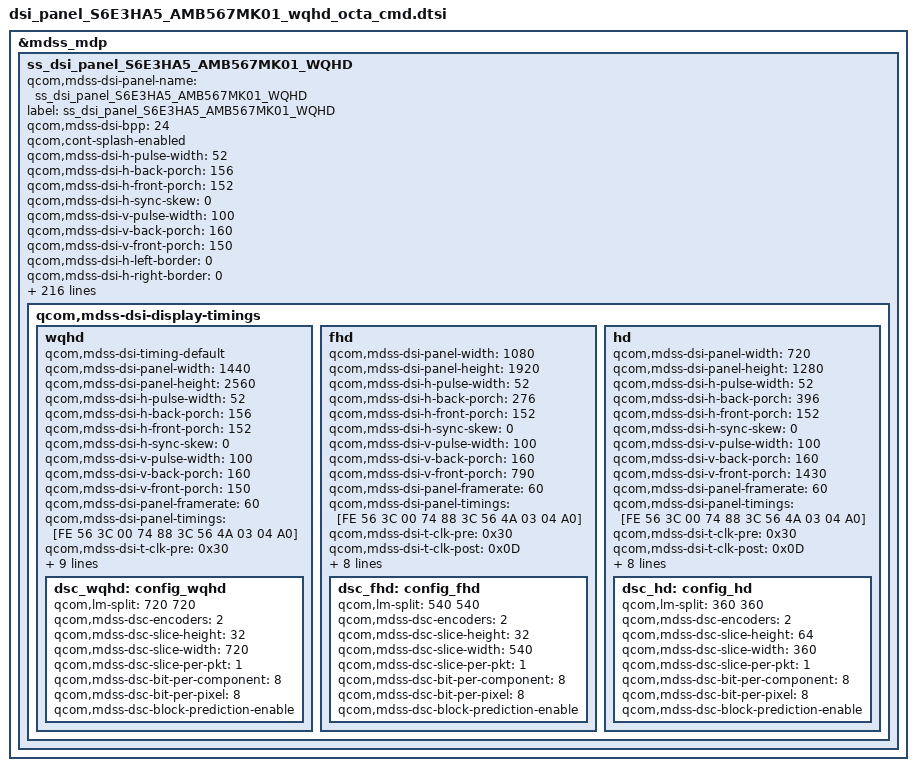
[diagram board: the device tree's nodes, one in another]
/* Copyright (c) 2012, Samsung Electronics Corporation. All rights reserved.
 *
 * This program is free software; you can redistribute it and/or modify
 * it under the terms of the GNU General Public License version 2 and
 * only version 2 as published by the Free Software Foundation.
 *
 * This program is distributed in the hope that it will be useful,
 * but WITHOUT ANY WARRANTY; without even the implied warranty of
 * MERCHANTABILITY or FITNESS FOR A PARTICULAR PURPOSE.  See the
 * GNU General Public License for more details.
 */

&mdss_mdp {
	ss_dsi_panel_S6E3HA5_AMB567MK01_WQHD: ss_dsi_panel_S6E3HA5_AMB567MK01_WQHD {
		qcom,mdss-dsi-panel-name = "ss_dsi_panel_S6E3HA5_AMB567MK01_WQHD";
		label = "ss_dsi_panel_S6E3HA5_AMB567MK01_WQHD";
		qcom,mdss-dsi-bpp = <24>;
		qcom,cont-splash-enabled;
		/*qcom,dcs-cmd-by-left;*/
		/*qcom,cmd-sync-wait-broadcast;*/
		/*qcom,cmd-sync-wait-trigger;*/
		/*qcom,mdss-dsi-fbc-enable=*/
		/*qcom,mdss-dsi-fbc-bpp=*/
		/*qcom,mdss-dsi-fbc-packing=*/
		/*qcom,mdss-dsi-fbc-quant-error=*/
		/*qcom,mdss-dsi-fbc-bias=*/
		/*qcom,mdss-dsi-fbc-pat-mode=*/
		/*qcom,mdss-dsi-fbc-vlc-mode=*/
		/*qcom,mdss-dsi-fbc-bflc-mode=*/
		/*qcom,mdss-dsi-fbc-h-line-budget=*/
		/*qcom,mdss-dsi-fbc-budget-ctrl=*/
		/*qcom,mdss-dsi-fbc-block-budget=*/
		/*qcom,mdss-dsi-fbc-lossless-threshold=*/
		/*qcom,mdss-dsi-fbc-lossy-threshold=*/
		/*qcom,mdss-dsi-fbc-rgb-threshold=*/
		/*qcom,mdss-dsi-fbc-lossy-mode-idx=*/

		qcom,mdss-dsi-h-pulse-width = <52>;
		qcom,mdss-dsi-h-back-porch = <156>;
		qcom,mdss-dsi-h-front-porch = <152>;
		qcom,mdss-dsi-h-sync-skew = <0>;
		qcom,mdss-dsi-v-pulse-width = <100>;
		qcom,mdss-dsi-v-back-porch = <160>;
		qcom,mdss-dsi-v-front-porch = <150>;

		qcom,mdss-dsi-h-left-border = <0>;
		qcom,mdss-dsi-h-right-border = <0>;
		qcom,mdss-dsi-v-top-border = <0>;
		qcom,mdss-dsi-v-bottom-border = <0>;

		qcom,mdss-dsi-underflow-color = <0xFF>;
		qcom,mdss-dsi-border-color = <0>;

		/*qcom,mdss-dsi-pan-enable-dynamic-fps=*/
		/*qcom,mdss-dsi-pan-fps-update=*/

		qcom,mdss-dsi-bl-pmic-control-type = "bl_ctrl_dcs";
		/*qcom,mdss-dsi-bl-pmic-bank-select=*/
		/*qcom,mdss-dsi-bl-pmic-pwm-frequency=*/
		/*qcom,mdss-dsi-pwm-gpio=*/

		qcom,mdss-dsi-bl-min-level = <1>;
		qcom,mdss-dsi-bl-max-level = <365>;
		qcom,mdss-brightness-max-level = <365>;
		qcom,mdss-dsi-interleave-mode = <0>;
		qcom,mdss-dsi-panel-type = "dsi_cmd_mode";

		/*qcom,mdss-dsi-te-check-enable; */
		qcom,mdss-dsi-te-using-te-pin;
		qcom,mdss-dsi-te-pin-select = <1>;

		/*qcom,dynamic-mode-switch-enabled;*/
		/*qcom,dynamic-mode-switch-type = "dynamic-switch-immediate";*/

		qcom,mdss-dsi-te-dcs-command = <1>;
		qcom,mdss-dsi-wr-mem-start = <0x2C>;
		qcom,mdss-dsi-wr-mem-continue = <0x3C>;

		/* CMD mode panel doesn't need below stuff */
		/*qcom,mdss-dsi-h-sync-pulse=*/
		/*qcom,mdss-dsi-hfp-power-mode=*/
		/*qcom,mdss-dsi-hbp-power-mode=*/
		/*qcom,mdss-dsi-hsa-power-mode=*/
		/*qcom,mdss-dsi-last-line-interleave=*/
		/*qcom,mdss-dsi-bllp-eof-power-mode=*/
		/*qcom,mdss-dsi-bllp-power-mode=*/
		/*qcom,mdss-dsi-traffic-mode=*/

		qcom,mdss-dsi-pixel-packing = "loose";

		qcom,mdss-dsi-virtual-channel-id = <0>;
		qcom,mdss-dsi-color-order = "rgb_swap_rgb";
		qcom,mdss-dsi-lane-0-state;
		qcom,mdss-dsi-lane-1-state;
		qcom,mdss-dsi-lane-2-state;
		qcom,mdss-dsi-lane-3-state;
		qcom,mdss-dsi-lane-map = "lane_map_0123";

		/* 60 FPS - DSC (width 480) */
		qcom,mdss-dsi-t-clk-pre = <0x30>;
		qcom,mdss-dsi-t-clk-post = <0xD>;

		qcom,mdss-dsi-stream = <0>;
		qcom,mdss-dsi-mdp-trigger = "none";
		qcom,mdss-dsi-dma-trigger = "trigger_sw";
		qcom,mdss-dsi-panel-framerate = <60>;
/*		qcom,mdss-dsi-panel-clockrate = <898000000>;*/
		qcom,mdss-dsi-off-command-state = "dsi_hs_mode";

		qcom,mdss-pan-physical-width-dimension = <71>; /* 70.73 */
		qcom,mdss-pan-physical-height-dimension = <125>; /* 125.44 */

		qcom,mdss-dsi-panel-mode-gpio-state = "invalid";

		/*qcom,mdss-tear-check-disable*/
/*		qcom,mdss-tear-check-sync-cfg-height = <2576>; */
		/*qcom,mdss-tear-check-sync-init-val=*/
		/*qcom,mdss-tear-check-sync-threshold-start=*/
		/*qcom,mdss-tear-check-sync-threshold-continue=*/
		/*qcom,mdss-tear-check-start-pos=*/
		/*qcom,mdss-tear-check-rd-ptr-trigger-intr=*/
		/*qcom,mdss-tear-check-frame-rate=*/

		qcom,mdss-dsi-reset-sequence = <1 5>, <0 5>, <1 5>;
		qcom,partial-update-enabled;
		/*qcom,partial-update-roi-merge;*/
		/*qcom,mdss-dsi-horizontal-line-idle*/

		qcom,mdss-dsi-lp11-init;
		qcom,mdss-dsi-init-delay-us = <1000>;

		qcom,mdss-dsi-rx-eot-ignore;
		qcom,mdss-dsi-tx-eot-append;

		qcom,ulps-enabled;
		/* qcom,suspend-ulps-enabled; */
		qcom,esd-check-enabled;
		qcom,mdss-dsi-panel-status-check-mode ="reg_read_irq";
		qcom,mdss-dsi-panel-status-value=<1>;
		/*qcom,mdss-dsi-panel-status-irq-trigger1 = "rising";*/
		qcom,mdss-dsi-panel-status-irq-trigger1 = "falling";

		qcom,mdss-dsi-off-command=[
			05 01 00 00 00 00 02 28 00
			29 01 00 00 00 00 03 9F A5 A5		/* LV1 (9F) unlock */
			05 01 00 00 00 00 02 10 00			/* wait 120ms(0x78) */
			29 01 00 00 78 00 03 9F 5A 5A		/* LV1 (9F) lock */
		];

		samsung,esd_recovery_1_tx_cmds_revA = [
			0A 01 00 00 00 00 58				/* PPS setting */
				11 00 00 89 30 80 0A
				00 05 A0 00 40 01 68
				01 68 02 00 01 B4 00
				20 04 F2 00 05 00 0C
				01 87 02 63 18 00 10
				F0 03 0C 20 00 06 0B
				0B 33 0E 1C 2A 38 46
				54 62 69 70 77 79 7B
				7D 7E 01 02 01 00 09
				40 09 BE 19 FC 19 FA
				19 F8 1A 38 1A 78 1A
				B6 2A F6 2B 34 2B 74
				3B 74 6B F4
		];

		samsung,esd_recovery_2_tx_cmds_revA = [
			0A 01 00 00 00 00 58				/* PPS setting */
				11 00 00 89 30 80 0A
				00 05 A0 00 40 01 68
				01 68 02 00 01 B4 00
				20 04 F2 00 05 00 0C
				01 87 02 63 18 00 10
				F0 03 0C 20 00 06 0B
				0B 33 0E 1C 2A 38 46
				54 62 69 70 77 79 7B
				7D 7E 01 02 01 00 09
				40 09 BE 19 FC 19 FA
				19 F8 1A 38 1A 78 1A
				B6 2A F6 2B 34 2B 74
				3B 74 6B F4
		];

		/*qcom,dynamic-mode-switch-enabled*/
		/*qcom,video-to-cmd-mode-switch-commands=*/
		/*qcom,cmd-to-video-mode-switch-commands=*/

/*
* ************************************************************************************************************************************
*
*
*			Below  parameters are samsung dependent thigs
*
*
* ************************************************************************************************************************************
*/
		samsung,support_panel_max = <1>;
		samsung,hw-config = "single_dsi";
		samsung,panel-lpm-enable;
		samsung,support_irc;
		samsung,elvss_interpolation_temperature = <(-15)>;
		samsung,support_factory_panel_swap;
		samsung,support_multires;

		/*
		* ************************************************************************************************************************
		*  Tx
		* ************************************************************************************************************************
		*/

		samsung,level1_key_enable_tx_cmds_revA = [
			29 01 00 00 00 00 03 F0 5A 5A
		];
		samsung,level1_key_disable_tx_cmds_revA = [
			29 01 00 00 00 00 03 F0 A5 A5
		];
		samsung,level2_key_enable_tx_cmds_revA = [
			29 01 00 00 00 00 03 F2 5A 5A
		];
		samsung,level2_key_disable_tx_cmds_revA = [
			29 01 00 00 00 00 03 F2 A5 A5
		];

		samsung,packet_size_tx_cmds_revA = [
			37 01 00 00 00 00 02 07 00
		];

		samsung,reg_read_pos_tx_cmds_revA = [
			15 01 00 00 00 00 02 B0 00
		];

		samsung,manufacture_read_pre_tx_cmds_revA = [
			05 01 00 00 78 00 01 11
			29 01 00 00 00 00 03 F0 5A 5A
		];

		samsung,display_on_tx_cmds_revA = [
			29 01 00 00 00 00 03 9F A5 A5		/* LV1 (9F) unlock */
			05 01 00 00 00 00 02 29 00
			29 01 00 00 00 00 03 9F 5A 5A		/* LV1 (9F) lock */
		];
		samsung,display_off_tx_cmds_revA = [05 01 00 00 00 00 02 28 00];

		/*
		* ************************************************************************************************************************
		*  Rx
		* ************************************************************************************************************************
		*/

		/*
			the last byte in read commands	represent READ LENGH, like below  READ LENGH = 0x21
		*/

		samsung,manufacture_id0_rx_cmds_revA = [ 06 01 00 00 00 00 01 da 01 00];
		samsung,manufacture_id1_rx_cmds_revA = [ 06 01 00 00 00 00 01 db 01 00];
		samsung,manufacture_id2_rx_cmds_revA = [ 06 01 00 00 00 00 01 dc 01 00];

		samsung,manufacture_id_rx_cmds_revA = [ 06 01 00 00 00 00 01 04 03 00];

		samsung,manufacture_date_rx_cmds_revA = [ 06 01 00 00 00 00 01 c8 04 28];	/* read C8 41~44th , 40=0x28*/

		samsung,cell_id_rx_cmds_revA = [ 06 01 00 00 00 00 01 C8 07 28]; /* read C8 41th~47th */
		samsung,octa_id_rx_cmds_revA = [ 06 01 00 00 00 00 01 C9 14 01]; /* read C9 2th~21th */

		samsung,ddi_id_rx_cmds_revA = [ 06 01 00 00 00 00 01 D6 05 00]; /* read D6 1th~5th */

		samsung,ldi_debug0_rx_cmds_revA = [06 01 00 00 00 00 01 0A 01 00];
		samsung,ldi_debug1_rx_cmds_revA = [06 01 00 00 00 00 01 ED 01 00];
		samsung,ldi_debug2_rx_cmds_revA = [06 01 00 00 00 00 01 EE 01 00];

		samsung,mtp_read_sysfs_rx_cmds_revA = [ 06 01 00 00 00 00 01 00 00 00];

		samsung,smart_dimming_mtp_rx_cmds_revA = [ 06 01 00 00 00 00 01 c8 23 00];

		samsung,mdnie_read_rx_cmds_revA = [ 06 01 00 00 00 00 01 A1 04 00];

		samsung,spi_enable_tx_cmds_revA = [
			29 01 00 00 00 00 03 F0 5A 5A
			29 01 00 00 00 00 03 FC 5A 5A
			29 01 00 00 00 00 02 B0 13
			29 01 00 00 00 00 02 D8 02
			29 01 00 00 00 00 02 B0 1F
			29 01 00 00 1E 00 02 FE 06
			29 01 00 00 00 00 03 F0 A5 A5
			29 01 00 00 00 00 03 FC A5 A5
		];

		/*
		* ************************************************************************************************************************
		*  SAMSUNG PANEL COVER CONTROL
		* ************************************************************************************************************************
		*/

		samsung,panel_cover_control_enable_cmds_revA = [
			29 01 00 00 00 00 03 F0 5A 5A
			29 01 00 00 00 00 02 B0 04
			29 01 00 00 00 00 03 F2 29 F0		/* LDI FPS Change(40.47hz) */
			29 01 00 00 00 00 03 F0 A5 A5
		];

		samsung,panel_cover_control_disable_cmds_revA = [
			29 01 00 00 00 00 03 F0 5A 5A
			29 01 00 00 00 00 02 B0 04
			29 01 00 00 00 00 03 F2 1C 70		/* LDI FPS Recovery(59.835hz) */
			29 01 00 00 00 00 03 F0 A5 A5
		];

		/*
		 * ************************************************************************************************************************
		 *   APLPM
		 * ************************************************************************************************************************
		 */

		/*
		 * The command set of R53h will be replaced with
		 * lpm 2nit or 40nit tx commnad for
		 * changing brightness level
		 */
		samsung,alpm_on_tx_cmds_revA = [
			29 01 00 00 00 00 03 F0 5A 5A		/* TEST KEY Enable */

			/* mDNIe BYPASS */
			39 01 00 00 00 00 38
				DF 00 6A 9A 25 1A 16 2A 00 37
				5A 00 4E C5 00 5D 17 00 30 C3
				FF 00 00 FF FF 00 FF 00 FF FF
				FF FF 00 FF FF 00 FF 00 FF 00
				00 FF FF 00 FF 00 FF 00 00 FF
				FF 00 FF 00 FF 00
			39 01 00 00 00 00 B8
				DE 00 00 00 24 96 B3 01 0E 01
				00 77 03 07 40 08 04 04 00 00
				0D E1 07 29 04 0F A0 00 03 7A
				A0 00 25 1C 24 00 48 EA FA 00
				10 00 10 00 9C 01 00 00 00 00
				DC 03 FF 40 80 C0 00 9A 00 9A
				00 9A 00 9A 00 00 00 00 00 00
				00 00 40 80 C0 01 0E 01 0E 01
				0E 01 0E 00 00 00 00 00 00 00
				00 01 0E 01 3A 01 44 00 01 00
				43 00 4B 00 18 00 1C 01 FF 01
				FF 03 FF E8 03 FF E8 80 00 28
				A0 01 00 01 00 01 00 00 10 00
				00 30 00 00 00 30 00 00 30 00
				00 00 FF 00 00 02 00 02 00 14
				00 01 00 01 00 10 00 00 28 3C
				01 00 00 10 20 30 40 50 60 70
				80 90 A0 B0 C0 D0 E0 F0 01 00
				00 00 00 00
			39 01 00 00 00 00 0F
				DD 01 00 08 00 00 00 00 00 00
				00 00 00 00 00

			29 01 00 00 00 00 02 B0 07			/* Global para(8th) */
			29 01 00 00 00 00 02 BB C1			/* ALPM(0xC1) Mode On */

			/* For TEST */
			29 01 00 00 00 00 02 B0 09			/* Global para(10th) */
			29 01 00 00 00 00 02 BB 0C			/* EQ Control */
			29 01 00 00 00 00 02 B0 0E			/* Global para(15th) */
			29 01 00 00 00 00 05 BB 07 07 07 07	/* EQ Control */
			29 01 00 00 00 00 02 B0 01			/* Global para(2nd) */
			29 01 00 00 00 00 02 F6 03			/* SAP Setting */

			29 01 00 00 00 00 02 53 03			/* ALPM/HLPM 2nit On*/
			29 01 00 00 00 00 03 B8 00 00		/* IRC OFF */
			29 01 00 00 01 00 02 F7 03			/* Gamma, LTPS(AID) update */
			29 01 00 00 00 00 02 F7 00
			29 01 00 00 00 00 03 F0 A5 A5
		];

		samsung,alpm_off_tx_cmds_revA = [
			29 01 00 00 00 00 03 F0 5A 5A	/* TEST KEY Enable */
			05 01 00 00 00 00 02 28 00		/* display off */
			/* image write for normal mode */
			29 01 00 00 23 00 02 53 00		/* HLPM/ALPM off & Wait 35ms(0x23ms) */
			29 01 00 00 01 00 02 F7 03		/* Gamma, LTPS(AID) update */
			29 01 00 00 00 00 02 F7 00
			29 01 00 00 00 00 03 F0 A5 A5	/* TEST KEY Disable */
		];

		samsung,lpm_2nit_tx_cmds_revA = [29 01 00 00 00 00 02 53 03];
		samsung,lpm_60nit_tx_cmds_revA = [29 01 00 00 00 00 02 53 02];

		samsung,lpm_ctrl_alpm_2nit_tx_cmds_revA = [29 01 00 00 00 00 02 BB C1];
		samsung,lpm_ctrl_alpm_60nit_tx_cmds_revA = [29 01 00 00 00 00 02 BB 81];
		samsung,lpm_ctrl_hlpm_2nit_tx_cmds_revA = [29 01 00 00 00 00 02 BB 41];
		samsung,lpm_ctrl_hlpm_60nit_tx_cmds_revA = [29 01 00 00 00 00 02 BB 01];

		/*
		* ************************************************************************************************************************
		*  VINT
		* ************************************************************************************************************************
		*/

		samsung,vint_tx_cmds_revA = [
			29 01 00 00 00 00 03 F4 BB 1E /* 420 ~ 14cd 0 */
			29 01 00 00 00 00 03 F4 BB 1D /* 13cd 1 */
			29 01 00 00 00 00 03 F4 BB 1C /* 12cd 2 */
			29 01 00 00 00 00 03 F4 BB 1B /* 11cd 3 */
			29 01 00 00 00 00 03 F4 BB 1A /* 10cd 4 */
			29 01 00 00 00 00 03 F4 BB 19 /* 9cd 5 */
			29 01 00 00 00 00 03 F4 BB 18 /* 8cd 6 */
			29 01 00 00 00 00 03 F4 BB 17 /* 7cd 7 */
			29 01 00 00 00 00 03 F4 BB 16 /* 6cd 8 */
			29 01 00 00 00 00 03 F4 BB 15 /* 5 ~ 2cd 9 */
		];

		samsung,vint_map_table_revA = <
			2	9		3	9		4	9		5	9		6	8
			7	7		8	6		9	5		10	4		11	3
			12	2		13	1		14	0		15	0		16	0
			17	0		19	0		20	0		21	0		22	0
			24	0		25	0		27	0		29	0		30	0
			32	0		34	0		37	0		39	0		41	0
			44	0		47	0		50	0		53	0		56	0
			60	0		64	0		68	0		72	0		77	0
			82	0		87	0		93	0		98	0		105	0
			111	0		119	0		126	0		134	0		143	0
			152	0		162	0		172	0		183	0		195	0
			207	0		220	0		234	0		249	0		265	0
			282	0		300	0		316	0		333	0		350	0
			357	0		365	0		372	0		380	0		387	0
			395	0		403	0		412	0		420	0
		>;

		/*
		* ************************************************************************************************************************
		*  GAMMA
		* ************************************************************************************************************************
		*/

		samsung,gamma_tx_cmds_revA = [
			29 01 00 00 00 00 24		/* Brightness Condition Set - Gamma 2.2 Setting*/
			CA 01 00 01 00 01 00 80
			80 80 80 80 80 80 80 80
			80 80 80 80 80 80 80 80
			80 80 80 80 80 80 80 00
			00 00 00 00
			29 01 00 00 00 00 02 F7 03		/* Gamma, LTPS(AID) update */

			29 01 00 00 00 00 3C		/* dummy for single transmission more 100ns delay */
			00 00 00 00 00 00 00 00 00 00
			00 00 00 00 00 00 00 00 00 00
			00 00 00 00 00 00 00 00 00 00
			00 00 00 00 00 00 00 00 00 00
			00 00 00 00 00 00 00 00 00 00
			00 00 00 00 00 00 00 00 00 00

			29 01 00 00 00 00 02 F7 00
		];

		/*
		* ************************************************************************************************************************
		*  HBM
		* ************************************************************************************************************************
		*/

		samsung,enter_hbm_lux = <10000>;
		samsung,hbm_rx_cmds_revA = [ 06 01 00 00 00 00 01 B3 21 02];	/* read B3 3rd~35th , 2=0x02 */
		samsung,hbm2_rx_cmds_revA = [ 06 01 00 00 00 00 01 B3 21 02];	/* read B3 3rd~35th , 2=0x02 */

		samsung,hbm_gamma_tx_cmds_revA = [
			29 01 00 00 00 00 24		/* Brightness Condition Set - Gamma 2.2 Setting*/
				CA 01 00 01 00 01 00 80
				80 80 80 80 80 80 80 80
				80 80 80 80 80 80 80 80
				80 80 80 80 80 80 80 00
				00 00 00 00
		];

		samsung,hbm_etc_tx_cmds_revA = [
			29 01 00 00 00 00 03 B1 00 0C		/* AID */
			29 01 00 00 00 00 04 B5 19 BC 00	/* ELVSS Setting */
			29 01 00 00 00 00 02 B0 17			/* Global para(24th) */
			29 01 00 00 00 00 02 B5 00 			/* ELVSS offset */
			29 01 00 00 00 00 03 F4 BB 1E		/* VINT set */
			29 01 00 00 00 00 08 B4 00 55 99 00 00 27 0A			/* ACL OPR Average Setting */
			29 01 00 00 00 00 02 55 02			/* ACL On */
			29 01 00 00 00 00 02 F7 03
			29 01 00 00 00 00 02 F7 00
		];

		samsung,hbm_irc_tx_cmds_revA = [
			29 00 00 00 00 00 15 B8 00 00
				00 00 00 00 00 00 00 00 00
				00 00 00 00 00 00 00 00 00
		];

		samsung,panel-hbm-off-cmds_revA = [
			15 01 00 00 00 00 02 53 00		/* HBM off*/
		];

		samsung,ccb_on_tx_cmds_revA = [
			29 01 00 00 00 00 03 F0 5A 5A
			29 00 00 00 00 00 03 B7 00 2A
			29 01 00 00 00 00 03 F0 A5 A5
		];

		samsung,ccb_off_tx_cmds_revA = [
			29 01 00 00 00 00 03 F0 5A 5A
			29 00 00 00 00 00 03 B7 00 2A
			29 01 00 00 00 00 03 F0 A5 A5
		];

		/*
		* ************************************************************************************************************************
		*  IRC
		* ************************************************************************************************************************
		*/

		samsung,irc_off_tx_cmds_revA = [
			29 01 00 00 00 00 02 B8 00	 /* IRC OFF */
		];

		samsung,irc_subdivision_tx_cmds_revA = [
			29 01 00 00 00 00 15 B8 6D B0 48 4C 95 DA 33 69 12 7A DA 00 00 00 00 00 00 00 00 00  /* 00 */
			29 01 00 00 00 00 15 B8 6D B0 48 4C 95 DA 33 69 12 7A DA 00 00 00 00 00 00 00 00 00  /* 01 */
			29 01 00 00 00 00 15 B8 6D B0 48 4C 95 DA 33 69 12 7A DA 00 00 00 00 00 00 00 00 00  /* 02 */
			29 01 00 00 00 00 15 B8 6D B0 48 4C 95 DA 33 69 12 7A DA 00 00 00 00 00 00 00 00 00  /* 03 */
			29 01 00 00 00 00 15 B8 6D B0 48 4C 95 DA 33 69 12 7A DA 00 00 00 00 00 00 00 00 00  /* 04 */
			29 01 00 00 00 00 15 B8 6D B0 48 4C 95 DA 33 69 12 7A DA 00 00 00 00 00 00 00 00 00  /* 05 */
			29 01 00 00 00 00 15 B8 6D B0 48 4C 95 DA 33 69 12 7A DA 00 00 00 00 00 00 00 00 00  /* 06 */
			29 01 00 00 00 00 15 B8 6D B0 48 4C 95 DA 33 69 12 7A DA 00 00 00 00 00 00 00 00 00  /* 07 */
			29 01 00 00 00 00 15 B8 6D B0 48 4C 95 DA 33 69 12 7A DA 00 00 00 00 00 00 00 00 00  /* 08 */
			29 01 00 00 00 00 15 B8 6D B0 48 4C 95 DA 33 69 12 7A DA 00 00 00 00 00 00 00 00 00  /* 09 */
			29 01 00 00 00 00 15 B8 6D B0 48 4C 95 DA 33 69 12 7A DA 00 00 00 00 00 00 00 00 00  /* 10 */
			29 01 00 00 00 00 15 B8 6D B0 48 4C 95 DA 33 69 12 7A DA 00 00 00 00 00 00 00 00 00  /* 11 */
			29 01 00 00 00 00 15 B8 6D B0 48 4C 95 DA 33 69 12 7A DA 00 00 00 00 00 00 00 00 00  /* 12 */
			29 01 00 00 00 00 15 B8 6D B0 48 4C 95 DA 33 69 12 7A DA 00 00 00 00 00 00 00 00 00  /* 13 */
			29 01 00 00 00 00 15 B8 6D B0 48 4C 95 DA 33 69 12 7A DA 00 00 00 00 00 00 00 00 00  /* 14 */
			29 01 00 00 00 00 15 B8 6D B0 48 4C 95 DA 33 69 12 7A DA 00 00 00 00 00 00 00 00 00  /* 15 */
			29 01 00 00 00 00 15 B8 6D B0 48 4C 95 DA 33 69 12 7A DA 00 00 00 00 00 00 00 00 00  /* 16 */
			29 01 00 00 00 00 15 B8 6D B0 48 4C 95 DA 33 69 12 7A DA 00 00 00 00 00 00 00 00 00  /* 17 */
			29 01 00 00 00 00 15 B8 6D B0 48 4C 95 DA 33 69 12 7A DA 00 00 00 00 00 00 00 00 00  /* 18 */
			29 01 00 00 00 00 15 B8 6D B0 48 4C 95 DA 33 69 12 7A DA 00 00 00 00 00 00 00 00 00  /* 19 */
			29 01 00 00 00 00 15 B8 6D B0 48 4C 95 DA 33 69 12 7A DA 00 00 00 00 00 00 00 00 00  /* 20 */
			29 01 00 00 00 00 15 B8 6D B0 48 4C 95 DA 33 69 12 7A DA 00 00 00 00 00 00 00 00 00  /* 21 */
			29 01 00 00 00 00 15 B8 6D B0 48 4C 95 DA 33 69 12 7A DA 00 00 00 00 00 00 00 00 00  /* 22 */
			29 01 00 00 00 00 15 B8 6D B0 48 4C 95 DA 33 69 12 7A DA 00 00 00 00 00 00 00 00 00  /* 23 */
			29 01 00 00 00 00 15 B8 6D B0 48 4C 95 DA 33 69 12 7A DA 00 00 00 00 00 00 00 00 00  /* 24 */
			29 01 00 00 00 00 15 B8 6D B0 48 4C 95 DA 33 69 12 7A DA 00 00 00 00 00 00 00 00 00  /* 25 */
			29 01 00 00 00 00 15 B8 6D B0 48 4C 95 DA 33 69 12 7A DA 00 00 00 00 00 00 00 00 00  /* 26 */
			29 01 00 00 00 00 15 B8 6D B0 48 4C 95 DA 33 69 12 7A DA 00 00 00 00 00 00 00 00 00  /* 27 */
			29 01 00 00 00 00 15 B8 6D B0 48 4C 95 DA 33 69 12 7A DA 00 00 00 00 00 00 00 00 00  /* 28 */
			29 01 00 00 00 00 15 B8 6D B0 48 4C 95 DA 33 69 12 7A DA 00 00 00 00 00 00 00 00 00  /* 29 */
			29 01 00 00 00 00 15 B8 6D B0 48 4C 95 DA 33 69 12 7A DA 00 00 00 00 00 00 00 00 00  /* 30 */
			29 01 00 00 00 00 15 B8 6D B0 48 4C 95 DA 33 69 12 7A DA 00 00 00 00 00 00 00 00 00  /* 31 */
			29 01 00 00 00 00 15 B8 6D B0 48 4C 95 DA 33 69 12 7A DA 00 00 00 00 00 00 00 00 00  /* 32 */
			29 01 00 00 00 00 15 B8 6D B0 48 4C 95 DA 33 69 12 7A DA 00 00 00 00 00 00 00 00 00  /* 33 */
			29 01 00 00 00 00 15 B8 6D B0 48 4C 95 DA 33 69 12 7A DA 00 00 00 00 00 00 00 00 00  /* 34 */
			29 01 00 00 00 00 15 B8 6D B0 48 4C 95 DA 33 69 12 7A DA 00 00 00 00 00 00 00 00 00  /* 35 */
			29 01 00 00 00 00 15 B8 6D B0 48 4C 95 DA 33 69 12 7A DA 00 00 00 00 00 00 00 00 00  /* 36 */
			29 01 00 00 00 00 15 B8 6D B0 48 4C 95 DA 33 69 12 7A DA 00 00 00 00 00 00 00 00 00  /* 37 */
			29 01 00 00 00 00 15 B8 6D B0 48 4C 95 DA 33 69 12 7A DA 00 00 00 00 00 00 00 00 00  /* 38 */
			29 01 00 00 00 00 15 B8 6D B0 48 4C 95 DA 33 69 12 7A DA 02 02 02 01 01 00 00 01 01  /* 39 */
			29 01 00 00 00 00 15 B8 6D B0 48 4C 95 DA 33 69 12 7A DA 02 02 02 01 01 00 00 01 01  /* 40 */
			29 01 00 00 00 00 15 B8 6D B0 48 4C 95 DA 33 69 12 7A DA 02 02 02 01 01 01 01 01 00  /* 41 */
			29 01 00 00 00 00 15 B8 6D B0 48 4C 95 DA 33 69 12 7A DA 02 02 02 01 01 01 01 01 00  /* 42 */
			29 01 00 00 00 00 15 B8 6D B0 48 4C 95 DA 33 69 12 7A DA 02 02 02 01 01 01 01 01 00  /* 43 */
			29 01 00 00 00 00 15 B8 6D B0 48 4C 95 DA 33 69 12 7A DA 02 02 02 01 01 01 01 01 00  /* 44 */
			29 01 00 00 00 00 15 B8 6D B0 48 4C 95 DA 33 69 12 7A DA 03 03 02 01 01 01 00 01 01  /* 45 */
			29 01 00 00 00 00 15 B8 6D B0 48 4C 95 DA 33 69 12 7A DA 03 03 02 01 01 01 00 01 01  /* 46 */
			29 01 00 00 00 00 15 B8 6D B0 48 4C 95 DA 33 69 12 7A DA 03 03 03 01 01 00 01 01 01  /* 47 */
			29 01 00 00 00 00 15 B8 6D B0 48 4C 95 DA 33 69 12 7A DA 03 03 03 01 01 00 01 01 01  /* 48 */
			29 01 00 00 00 00 15 B8 6D B0 48 4C 95 DA 33 69 12 7A DA 03 03 03 01 01 01 01 01 00  /* 49 */
			29 01 00 00 00 00 15 B8 6D B0 48 4C 95 DA 33 69 12 7A DA 03 03 03 01 01 01 01 01 00  /* 50 */
			29 01 00 00 00 00 15 B8 6D B0 48 4C 95 DA 33 69 12 7A DA 03 03 03 01 02 01 01 01 00  /* 51 */
			29 01 00 00 00 00 15 B8 6D B0 48 4C 95 DA 33 69 12 7A DA 03 03 03 01 02 01 01 01 00  /* 52 */
			29 01 00 00 00 00 15 B8 6D B0 48 4C 95 DA 33 69 12 7A DA 04 03 03 01 02 01 01 01 01  /* 53 */
			29 01 00 00 00 00 15 B8 6D B0 48 4C 95 DA 33 69 12 7A DA 04 03 03 01 02 01 01 01 01  /* 54 */
			29 01 00 00 00 00 15 B8 6D B0 48 4C 95 DA 33 69 12 7A DA 04 04 03 01 01 01 01 01 01  /* 55 */
			29 01 00 00 00 00 15 B8 6D B0 48 4C 95 DA 33 69 12 7A DA 04 04 03 01 01 02 01 02 00  /* 56 */
			29 01 00 00 00 00 15 B8 6D B0 48 4C 95 DA 33 69 12 7A DA 04 04 04 01 02 01 01 01 01  /* 57 */
			29 01 00 00 00 00 15 B8 6D B0 48 4C 95 DA 33 69 12 7A DA 04 04 04 02 02 01 01 01 01  /* 58 */
			29 01 00 00 00 00 15 B8 6D B0 48 4C 95 DA 33 69 12 7A DA 04 04 04 02 02 01 01 01 01  /* 59 */
			29 01 00 00 00 00 15 B8 6D B0 48 4C 95 DA 33 69 12 7A DA 05 04 04 01 02 01 01 02 01  /* 60 */
			29 01 00 00 00 00 15 B8 6D B0 48 4C 95 DA 33 69 12 7A DA 05 04 04 01 02 01 01 02 01  /* 61 */
			29 01 00 00 00 00 15 B8 6D B0 48 4C 95 DA 33 69 12 7A DA 05 05 04 01 02 02 01 01 00  /* 62 */
			29 01 00 00 00 00 15 B8 6D B0 48 4C 95 DA 33 69 12 7A DA 05 05 04 02 02 02 01 01 01  /* 63 */
			29 01 00 00 00 00 15 B8 6D B0 48 4C 95 DA 33 69 12 7A DA 05 05 05 02 02 01 01 02 01  /* 64 */
			29 01 00 00 00 00 15 B8 6D B0 48 4C 95 DA 33 69 12 7A DA 05 05 05 02 02 01 01 02 01  /* 65 */
			29 01 00 00 00 00 15 B8 6D B0 48 4C 95 DA 33 69 12 7A DA 05 05 05 02 02 01 01 02 01  /* 66 */
			29 01 00 00 00 00 15 B8 6D B0 48 4C 95 DA 33 69 12 7A DA 06 05 05 01 03 02 02 01 01  /* 67 */
			29 01 00 00 00 00 15 B8 6D B0 48 4C 95 DA 33 69 12 7A DA 06 06 05 02 02 02 01 02 01  /* 68 */
			29 01 00 00 00 00 15 B8 6D B0 48 4C 95 DA 33 69 12 7A DA 06 06 05 02 02 02 01 02 01  /* 69 */
			29 01 00 00 00 00 15 B8 6D B0 48 4C 95 DA 33 69 12 7A DA 06 06 06 02 03 01 02 02 01  /* 70 */
			29 01 00 00 00 00 15 B8 6D B0 48 4C 95 DA 33 69 12 7A DA 06 06 06 02 03 02 02 02 01  /* 71 */
			29 01 00 00 00 00 15 B8 6D B0 48 4C 95 DA 33 69 12 7A DA 07 06 06 02 03 02 01 02 01  /* 72 */
			29 01 00 00 00 00 15 B8 6D B0 48 4C 95 DA 33 69 12 7A DA 07 07 06 02 03 02 02 02 01  /* 73 */
			29 01 00 00 00 00 15 B8 6D B0 48 4C 95 DA 33 69 12 7A DA 07 07 06 02 03 02 02 02 01  /* 74 */
			29 01 00 00 00 00 15 B8 6D B0 48 4C 95 DA 33 69 12 7A DA 07 07 07 03 03 02 02 03 01  /* 75 */
			29 01 00 00 00 00 15 B8 6D B0 48 4C 95 DA 33 69 12 7A DA 08 07 07 02 04 02 02 02 01  /* 76 */
			29 01 00 00 00 00 15 B8 6D B0 48 4C 95 DA 33 69 12 7A DA 08 08 07 02 03 02 02 02 02  /* 77 */
			29 01 00 00 00 00 15 B8 6D B0 48 4C 95 DA 33 69 12 7A DA 08 08 07 03 03 02 02 03 02  /* 78 */
			29 01 00 00 00 00 15 B8 6D B0 48 4C 95 DA 33 69 12 7A DA 08 08 07 03 04 03 02 02 01  /* 79 */
			29 01 00 00 00 00 15 B8 6D B0 48 4C 95 DA 33 69 12 7A DA 08 08 08 03 04 02 02 02 01  /* 80 */
			29 01 00 00 00 00 15 B8 6D B0 48 4C 95 DA 33 69 12 7A DA 09 09 08 03 03 02 02 03 02  /* 81 */
			29 01 00 00 00 00 15 B8 6D B0 48 4C 95 DA 33 69 12 7A DA 09 09 08 03 04 03 02 02 01  /* 82 */
			29 01 00 00 00 00 15 B8 6D B0 48 4C 95 DA 33 69 12 7A DA 0A 09 08 02 04 03 03 03 02  /* 83 */
			29 01 00 00 00 00 15 B8 6D B0 48 4C 95 DA 33 69 12 7A DA 0A 0A 09 03 04 02 02 02 02  /* 84 */
			29 01 00 00 00 00 15 B8 6D B0 48 4C 95 DA 33 69 12 7A DA 0A 0A 09 03 04 03 03 03 02  /* 85 */
			29 01 00 00 00 00 15 B8 6D B0 48 4C 95 DA 33 69 12 7A DA 0A 0A 09 04 04 03 02 04 02  /* 86 */
			29 01 00 00 00 00 15 B8 6D B0 48 4C 95 DA 33 69 12 7A DA 0B 0B 0A 03 04 03 03 03 01  /* 87 */
			29 01 00 00 00 00 15 B8 6D B0 48 4C 95 DA 33 69 12 7A DA 0B 0B 0A 03 04 03 03 04 02  /* 88 */
			29 01 00 00 00 00 15 B8 6D B0 48 4C 95 DA 33 69 12 7A DA 0B 0B 0A 04 05 03 03 03 02  /* 89 */
			29 01 00 00 00 00 15 B8 6D B0 48 4C 95 DA 33 69 12 7A DA 0C 0B 0A 03 05 04 03 04 02  /* 90 */
			29 01 00 00 00 00 15 B8 6D B0 48 4C 95 DA 33 69 12 7A DA 0C 0C 0B 04 05 03 03 03 02  /* 91 */
			29 01 00 00 00 00 15 B8 6D B0 48 4C 95 DA 33 69 12 7A DA 0C 0C 0B 04 05 04 03 04 02  /* 92 */
			29 01 00 00 00 00 15 B8 6D B0 48 4C 95 DA 33 69 12 7A DA 0D 0D 0B 04 05 04 03 04 02  /* 93 */
			29 01 00 00 00 00 15 B8 6D B0 48 4C 95 DA 33 69 12 7A DA 0D 0D 0C 04 05 04 04 04 02  /* 94 */
			29 01 00 00 00 00 15 B8 6D B0 48 4C 95 DA 33 69 12 7A DA 0E 0D 0C 04 06 04 03 04 02  /* 95 */
			29 01 00 00 00 00 15 B8 6D B0 48 4C 95 DA 33 69 12 7A DA 0E 0E 0C 04 06 05 04 04 02  /* 96 */
			29 01 00 00 00 00 15 B8 6D B0 48 4C 95 DA 33 69 12 7A DA 0F 0E 0D 04 06 04 04 05 03  /* 97 */
			29 01 00 00 00 00 15 B8 6D B0 48 4C 95 DA 33 69 12 7A DA 0F 0F 0D 05 06 04 03 04 03  /* 98 */
			29 01 00 00 00 00 15 B8 6D B0 48 4C 95 DA 33 69 12 7A DA 10 0F 0E 04 07 04 04 04 03  /* 99 */
			29 01 00 00 00 00 15 B8 6D B0 48 4C 95 DA 33 69 12 7A DA 10 10 0E 05 06 05 04 05 02  /* 100 */
			29 01 00 00 00 00 15 B8 6D B0 48 4C 95 DA 33 69 12 7A DA 11 10 0F 05 07 04 04 05 03  /* 101 */
			29 01 00 00 00 00 15 B8 6D B0 48 4C 95 DA 33 69 12 7A DA 11 11 0F 05 07 05 05 05 03  /* 102 */
			29 01 00 00 00 00 15 B8 6D B0 48 4C 95 DA 33 69 12 7A DA 12 11 10 05 07 05 05 06 03  /* 103 */
			29 01 00 00 00 00 15 B8 6D B0 48 4C 95 DA 33 69 12 7A DA 12 12 10 06 07 05 04 05 03  /* 104 */
			29 01 00 00 00 00 15 B8 6D B0 48 4C 95 DA 33 69 12 7A DA 13 12 11 05 08 05 05 06 03  /* 105 */
			29 01 00 00 00 00 15 B8 6D B0 48 4C 95 DA 33 69 12 7A DA 13 13 11 06 08 06 05 06 03  /* 106 */
			29 01 00 00 00 00 15 B8 6D B0 48 4C 95 DA 33 69 12 7A DA 14 13 12 06 09 05 05 06 04  /* 107 */
			29 01 00 00 00 00 15 B8 6D B0 48 4C 95 DA 33 69 12 7A DA 14 14 12 07 08 06 05 06 03  /* 108 */
			29 01 00 00 00 00 15 B8 6D B0 48 4C 95 DA 33 69 12 7A DA 15 15 13 07 08 06 05 07 03  /* 109 */
			29 01 00 00 00 00 15 B8 6D B0 48 4C 95 DA 33 69 12 7A DA 16 15 13 07 09 07 05 07 03  /* 110 */
			29 01 00 00 00 00 15 B8 6D B0 48 4C 95 DA 33 69 12 7A DA 16 16 14 07 09 06 06 07 04  /* 111 */
			29 01 00 00 00 00 15 B8 6D B0 48 4C 95 DA 33 69 12 7A DA 17 16 14 07 0A 07 06 07 04  /* 112 */
			29 01 00 00 00 00 15 B8 6D B0 48 4C 95 DA 33 69 12 7A DA 18 17 15 07 0A 07 06 07 04  /* 113 */
			29 01 00 00 00 00 15 B8 6D B0 48 4C 95 DA 33 69 12 7A DA 19 18 16 07 0A 07 07 08 04  /* 114 */
			29 01 00 00 00 00 15 B8 6D B0 48 4C 95 DA 33 69 12 7A DA 19 19 17 08 0A 07 07 08 04  /* 115 */
			29 01 00 00 00 00 15 B8 6D B0 48 4C 95 DA 33 69 12 7A DA 1A 1A 17 08 0A 08 07 08 04  /* 116 */
			29 01 00 00 00 00 15 B8 6D B0 48 4C 95 DA 33 69 12 7A DA 1B 1A 18 08 0B 08 07 09 04  /* 117 */
			29 01 00 00 00 00 15 B8 6D B0 48 4C 95 DA 33 69 12 7A DA 1C 1B 19 08 0C 08 07 08 04  /* 118 */
			29 01 00 00 00 00 15 B8 6D B0 48 4C 95 DA 33 69 12 7A DA 1D 1C 19 09 0C 09 07 09 05  /* 119 */
			29 01 00 00 00 00 15 B8 6D B0 48 4C 95 DA 33 69 12 7A DA 1E 1D 1A 09 0C 09 07 09 05  /* 120 */
			29 01 00 00 00 00 15 B8 6D B0 48 4C 95 DA 33 69 12 7A DA 1F 1E 1B 09 0D 09 08 09 05  /* 121 */
			29 01 00 00 00 00 15 B8 6D B0 48 4C 95 DA 33 69 12 7A DA 1F 1F 1C 0A 0D 09 08 09 05  /* 122 */
			29 01 00 00 00 00 15 B8 6D B0 48 4C 95 DA 33 69 12 7A DA 21 20 1D 0A 0D 09 08 0A 06  /* 123 */
			29 01 00 00 00 00 15 B8 6D B0 48 4C 95 DA 33 69 12 7A DA 22 21 1E 0A 0E 09 08 0A 06  /* 124 */
			29 01 00 00 00 00 15 B8 6D B0 48 4C 95 DA 33 69 12 7A DA 23 22 1F 0A 0E 0A 09 0A 06  /* 125 */
			29 01 00 00 00 00 15 B8 6D B0 48 4C 95 DA 33 69 12 7A DA 24 23 20 0B 0F 0A 09 0A 06  /* 126 */
			29 01 00 00 00 00 15 B8 6D B0 48 4C 95 DA 33 69 12 7A DA 25 24 21 0B 0F 0A 0A 0B 07  /* 127 */
			29 01 00 00 00 00 15 B8 6D B0 48 4C 95 DA 33 69 12 7A DA 26 25 22 0C 10 0A 09 0B 07  /* 128 */
			29 01 00 00 00 00 15 B8 6D B0 48 4C 95 DA 33 69 12 7A DA 26 25 22 0C 10 0B 0A 0C 07  /* 129 */
			29 01 00 00 00 00 15 B8 6D B0 48 4C 95 DA 33 69 12 7A DA 27 26 22 0B 10 0B 0A 0B 07  /* 130 */
			29 01 00 00 00 00 15 B8 6D B0 48 4C 95 DA 33 69 12 7A DA 27 26 22 0C 10 0C 0A 0C 06  /* 131 */
			29 01 00 00 00 00 15 B8 6D B0 48 4C 95 DA 33 69 12 7A DA 27 26 23 0D 11 0B 0A 0C 07  /* 132 */
			29 01 00 00 00 00 15 B8 6D B0 48 4C 95 DA 33 69 12 7A DA 28 27 23 0C 10 0C 0A 0C 06  /* 133 */
			29 01 00 00 00 00 15 B8 6D B0 48 4C 95 DA 33 69 12 7A DA 28 27 23 0C 11 0C 0A 0C 07  /* 134 */
			29 01 00 00 00 00 15 B8 6D B0 48 4C 95 DA 33 69 12 7A DA 28 27 24 0D 11 0B 0A 0C 07  /* 135 */
			29 01 00 00 00 00 15 B8 6D B0 48 4C 95 DA 33 69 12 7A DA 29 28 24 0C 11 0C 0B 0C 07  /* 136 */
			29 01 00 00 00 00 15 B8 6D B0 48 4C 95 DA 33 69 12 7A DA 29 28 24 0D 11 0C 0A 0C 07  /* 137 */
			29 01 00 00 00 00 15 B8 6D B0 48 4C 95 DA 33 69 12 7A DA 29 28 25 0D 12 0C 0B 0C 07  /* 138 */
			29 01 00 00 00 00 15 B8 6D B0 48 4C 95 DA 33 69 12 7A DA 2A 29 25 0D 11 0C 0A 0D 07  /* 139 */
			29 01 00 00 00 00 15 B8 6D B0 48 4C 95 DA 33 69 12 7A DA 2A 29 25 0D 12 0D 0B 0C 07  /* 140 */
			29 01 00 00 00 00 15 B8 6D B0 48 4C 95 DA 33 69 12 7A DA 2A 29 26 0E 12 0C 0A 0D 07  /* 141 */
			29 01 00 00 00 00 15 B8 6D B0 48 4C 95 DA 33 69 12 7A DA 2B 2A 26 0D 12 0C 0B 0C 08  /* 142 */
			29 01 00 00 00 00 15 B8 6D B0 48 4C 95 DA 33 69 12 7A DA 2B 2A 26 0E 12 0D 0B 0D 07  /* 143 */
			29 01 00 00 00 00 15 B8 6D B0 48 4C 95 DA 33 69 12 7A DA 2C 2B 27 0D 12 0C 0B 0D 08  /* 144 */
			29 01 00 00 00 00 15 B8 6D B0 48 4C 95 DA 33 69 12 7A DA 2C 2B 27 0E 12 0D 0B 0E 07  /* 145 */
			29 01 00 00 00 00 15 B8 6D B0 48 4C 95 DA 33 69 12 7A DA 2C 2B 27 0E 13 0D 0B 0D 08  /* 146 */
			29 01 00 00 00 00 15 B8 6D B0 48 4C 95 DA 33 69 12 7A DA 2D 2C 28 0E 12 0C 0B 0E 08  /* 147 */
			29 01 00 00 00 00 15 B8 6D B0 48 4C 95 DA 33 69 12 7A DA 2D 2C 28 0E 13 0D 0C 0D 08  /* 148 */
			29 01 00 00 00 00 15 B8 6D B0 48 4C 95 DA 33 69 12 7A DA 2E 2D 28 0E 12 0D 0B 0E 08  /* 149 */
			29 01 00 00 00 00 15 B8 6D B0 48 4C 95 DA 33 69 12 7A DA 2E 2D 29 0E 13 0D 0C 0E 08  /* 150 */
			29 01 00 00 00 00 15 B8 6D B0 48 4C 95 DA 33 69 12 7A DA 2E 2D 29 0F 14 0D 0C 0D 08  /* 151 */
			29 01 00 00 00 00 15 B8 6D B0 48 4C 95 DA 33 69 12 7A DA 2F 2E 29 0E 13 0E 0C 0E 08  /* 152 */
			29 01 00 00 00 00 15 B8 6D B0 48 4C 95 DA 33 69 12 7A DA 2F 2E 2A 0F 13 0D 0C 0E 08  /* 153 */
			29 01 00 00 00 00 15 B8 6D B0 48 4C 95 DA 33 69 12 7A DA 2F 2E 2A 0F 14 0E 0C 0E 08  /* 154 */
			29 01 00 00 00 00 15 B8 6D B0 48 4C 95 DA 33 69 12 7A DA 30 2F 2A 0F 14 0E 0C 0E 08  /* 155 */
			29 01 00 00 00 00 15 B8 6D B0 48 4C 95 DA 33 69 12 7A DA 30 2F 2B 0F 14 0D 0C 0E 09  /* 156 */
			29 01 00 00 00 00 15 B8 6D B0 48 4C 95 DA 33 69 12 7A DA 30 2F 2B 10 14 0E 0C 0F 08  /* 157 */
			29 01 00 00 00 00 15 B8 6D B0 48 4C 95 DA 33 69 12 7A DA 31 30 2B 0F 14 0E 0C 0F 09  /* 158 */
			29 01 00 00 00 00 15 B8 6D B0 48 4C 95 DA 33 69 12 7A DA 31 30 2C 10 15 0E 0C 0E 08  /* 159 */
			29 01 00 00 00 00 15 B8 6D B0 48 4C 95 DA 33 69 12 7A DA 32 31 2C 0F 14 0E 0D 0F 09  /* 160 */
			29 01 00 00 00 00 15 B8 6D B0 48 4C 95 DA 33 69 12 7A DA 32 31 2C 10 15 0F 0C 0F 08  /* 161 */
			29 01 00 00 00 00 15 B8 6D B0 48 4C 95 DA 33 69 12 7A DA 32 31 2D 10 15 0E 0D 0F 09  /* 162 */
			29 01 00 00 00 00 15 B8 6D B0 48 4C 95 DA 33 69 12 7A DA 33 32 2D 10 15 0F 0C 0F 08  /* 163 */
			29 01 00 00 00 00 15 B8 6D B0 48 4C 95 DA 33 69 12 7A DA 33 32 2D 10 15 0F 0D 0F 09  /* 164 */
			29 01 00 00 00 00 15 B8 6D B0 48 4C 95 DA 33 69 12 7A DA 34 32 2E 10 16 0E 0D 0F 09  /* 165 */
			29 01 00 00 00 00 15 B8 6D B0 48 4C 95 DA 33 69 12 7A DA 34 33 2E 10 15 0F 0D 10 09  /* 166 */
			29 01 00 00 00 00 15 B8 6D B0 48 4C 95 DA 33 69 12 7A DA 34 33 2E 11 16 0F 0D 10 09  /* 167 */
			29 01 00 00 00 00 15 B8 6D B0 48 4C 95 DA 33 69 12 7A DA 35 33 2F 10 16 0F 0D 10 09  /* 168 */
			29 01 00 00 00 00 15 B8 6D B0 48 4C 95 DA 33 69 12 7A DA 35 34 2F 10 16 0F 0E 10 09  /* 169 */
			29 01 00 00 00 00 15 B8 6D B0 48 4C 95 DA 33 69 12 7A DA 35 34 2F 11 16 10 0E 10 09  /* 170 */
			29 01 00 00 00 00 15 B8 6D B0 48 4C 95 DA 33 69 12 7A DA 36 35 30 11 16 0F 0D 10 09  /* 171 */
			29 01 00 00 00 00 15 B8 6D B0 48 4C 95 DA 33 69 12 7A DA 36 35 30 11 16 0F 0E 10 0A  /* 172 */
			29 01 00 00 00 00 15 B8 6D B0 48 4C 95 DA 33 69 12 7A DA 36 35 30 11 17 10 0E 10 09  /* 173 */
			29 01 00 00 00 00 15 B8 6D B0 48 4C 95 DA 33 69 12 7A DA 37 36 31 11 16 0F 0E 11 0A  /* 174 */
			29 01 00 00 00 00 15 B8 6D B0 48 4C 95 DA 33 69 12 7A DA 37 36 31 11 17 10 0E 10 09  /* 175 */
			29 01 00 00 00 00 15 B8 6D B0 48 4C 95 DA 33 69 12 7A DA 38 36 31 11 17 10 0E 11 0A  /* 176 */
			29 01 00 00 00 00 15 B8 6D B0 48 4C 95 DA 33 69 12 7A DA 38 37 32 12 17 10 0E 11 09  /* 177 */
			29 01 00 00 00 00 15 B8 6D B0 48 4C 95 DA 33 69 12 7A DA 39 37 32 11 18 10 0E 11 0A  /* 178 */
			29 01 00 00 00 00 15 B8 6D B0 48 4C 95 DA 33 69 12 7A DA 39 37 32 11 18 11 0F 11 09  /* 179 */
			29 01 00 00 00 00 15 B8 6D B0 48 4C 95 DA 33 69 12 7A DA 39 38 33 12 18 10 0E 11 0A  /* 180 */
			29 01 00 00 00 00 15 B8 6D B0 48 4C 95 DA 33 69 12 7A DA 3A 38 33 11 18 11 0F 11 09  /* 181 */
			29 01 00 00 00 00 15 B8 6D B0 48 4C 95 DA 33 69 12 7A DA 3A 39 33 12 18 11 0F 11 0A  /* 182 */
			29 01 00 00 00 00 15 B8 6D B0 48 4C 95 DA 33 69 12 7A DA 3A 39 34 13 18 10 0E 12 0B  /* 183 */
			29 01 00 00 00 00 15 B8 6D B0 48 4C 95 DA 33 69 12 7A DA 3B 39 34 12 19 11 0F 11 0A  /* 184 */
			29 01 00 00 00 00 15 B8 6D B0 48 4C 95 DA 33 69 12 7A DA 3B 3A 34 13 18 11 0F 12 0B  /* 185 */
			29 01 00 00 00 00 15 B8 6D B0 48 4C 95 DA 33 69 12 7A DA 3B 3A 35 13 19 11 0F 11 0A  /* 186 */
			29 01 00 00 00 00 15 B8 6D B0 48 4C 95 DA 33 69 12 7A DA 3C 3A 35 12 19 11 10 12 0B  /* 187 */
			29 01 00 00 00 00 15 B8 6D B0 48 4C 95 DA 33 69 12 7A DA 3C 3B 35 13 19 12 0F 12 0A  /* 188 */
			29 01 00 00 00 00 15 B8 6D B0 48 4C 95 DA 33 69 12 7A DA 3D 3B 36 13 19 11 0F 13 0B  /* 189 */
			29 01 00 00 00 00 15 B8 6D B0 48 4C 95 DA 33 69 12 7A DA 3D 3C 36 13 19 12 10 12 0A  /* 190 */
			29 01 00 00 00 00 15 B8 6D B0 48 4C 95 DA 33 69 12 7A DA 3D 3C 36 13 19 12 10 13 0A  /* 191 */
			29 01 00 00 00 00 15 B8 6D B0 48 4C 95 DA 33 69 12 7A DA 3E 3C 37 13 1A 11 0F 12 0B  /* 192 */
			29 01 00 00 00 00 15 B8 6D B0 48 4C 95 DA 33 69 12 7A DA 3E 3D 37 13 19 12 10 13 0B  /* 193 */
			29 01 00 00 00 00 15 B8 6D B0 48 4C 95 DA 33 69 12 7A DA 3F 3D 37 13 1A 12 10 13 0B  /* 194 */
			29 01 00 00 00 00 15 B8 6D B0 48 4C 95 DA 33 69 12 7A DA 3F 3E 38 14 1A 12 0F 12 0B  /* 195 */
			29 01 00 00 00 00 15 B8 6D B0 48 4C 95 DA 33 69 12 7A DA 3F 3E 38 14 1A 12 10 13 0B  /* 196 */
			29 01 00 00 00 00 15 B8 6D B0 48 4C 95 DA 33 69 12 7A DA 40 3E 38 14 1B 13 10 13 0B  /* 197 */
			29 01 00 00 00 00 15 B8 6D B0 48 4C 95 DA 33 69 12 7A DA 40 3F 39 14 1A 12 10 14 0B  /* 198 */
			29 01 00 00 00 00 15 B8 6D B0 48 4C 95 DA 33 69 12 7A DA 41 3F 39 14 1B 13 10 13 0B  /* 199 */
			29 01 00 00 00 00 15 B8 6D B0 48 4C 95 DA 33 69 12 7A DA 41 40 3A 14 1A 12 11 14 0B  /* 200 */
			29 01 00 00 00 00 15 B8 6D B0 48 4C 95 DA 33 69 12 7A DA 41 40 3A 15 1B 13 10 14 0B  /* 201 */
			29 01 00 00 00 00 15 B8 6D B0 48 4C 95 DA 33 69 12 7A DA 42 40 3A 14 1C 13 11 13 0C  /* 202 */
			29 01 00 00 00 00 15 B8 6D B0 48 4C 95 DA 33 69 12 7A DA 42 41 3B 15 1B 13 11 14 0B  /* 203 */
			29 01 00 00 00 00 15 B8 6D B0 48 4C 95 DA 33 69 12 7A DA 43 41 3B 14 1C 13 11 14 0C  /* 204 */
			29 01 00 00 00 00 15 B8 6D B0 48 4C 95 DA 33 69 12 7A DA 43 42 3B 15 1B 14 11 14 0B  /* 205 */
			29 01 00 00 00 00 15 B8 6D B0 48 4C 95 DA 33 69 12 7A DA 43 42 3C 15 1C 13 11 14 0C  /* 206 */
			29 01 00 00 00 00 15 B8 6D B0 48 4C 95 DA 33 69 12 7A DA 44 42 3C 15 1C 13 11 14 0C  /* 207 */
			29 01 00 00 00 00 15 B8 6D B0 48 4C 95 DA 33 69 12 7A DA 44 43 3C 15 1C 14 12 14 0C  /* 208 */
			29 01 00 00 00 00 15 B8 6D B0 48 4C 95 DA 33 69 12 7A DA 45 43 3D 15 1C 13 11 15 0C  /* 209 */
			29 01 00 00 00 00 15 B8 6D B0 48 4C 95 DA 33 69 12 7A DA 45 43 3D 15 1D 14 12 15 0C  /* 210 */
			29 01 00 00 00 00 15 B8 6D B0 48 4C 95 DA 33 69 12 7A DA 45 44 3D 16 1D 14 11 14 0C  /* 211 */
			29 01 00 00 00 00 15 B8 6D B0 48 4C 95 DA 33 69 12 7A DA 46 44 3E 15 1D 14 12 15 0C  /* 212 */
			29 01 00 00 00 00 15 B8 6D B0 48 4C 95 DA 33 69 12 7A DA 46 45 3E 16 1D 14 12 15 0C  /* 213 */
			29 01 00 00 00 00 15 B8 6D B0 48 4C 95 DA 33 69 12 7A DA 47 45 3F 16 1D 14 11 15 0C  /* 214 */
			29 01 00 00 00 00 15 B8 6D B0 48 4C 95 DA 33 69 12 7A DA 47 45 3F 16 1E 14 12 15 0C  /* 215 */
			29 01 00 00 00 00 15 B8 6D B0 48 4C 95 DA 33 69 12 7A DA 47 46 3F 16 1D 15 12 15 0C  /* 216 */
			29 01 00 00 00 00 15 B8 6D B0 48 4C 95 DA 33 69 12 7A DA 48 46 3F 16 1E 15 12 15 0C  /* 217 */
			29 01 00 00 00 00 15 B8 6D B0 48 4C 95 DA 33 69 12 7A DA 48 46 40 16 1E 15 13 16 0C  /* 218 */
			29 01 00 00 00 00 15 B8 6D B0 48 4C 95 DA 33 69 12 7A DA 49 47 40 16 1E 15 12 16 0D  /* 219 */
			29 01 00 00 00 00 15 B8 6D B0 48 4C 95 DA 33 69 12 7A DA 49 47 41 17 1E 14 12 16 0D  /* 220 */
			29 01 00 00 00 00 15 B8 6D B0 48 4C 95 DA 33 69 12 7A DA 49 48 41 17 1E 15 13 16 0D  /* 221 */
			29 01 00 00 00 00 15 B8 6D B0 48 4C 95 DA 33 69 12 7A DA 4A 48 41 16 1E 15 13 16 0D  /* 222 */
			29 01 00 00 00 00 15 B8 6D B0 48 4C 95 DA 33 69 12 7A DA 4A 48 41 17 1F 16 13 16 0C  /* 223 */
			29 01 00 00 00 00 15 B8 6D B0 48 4C 95 DA 33 69 12 7A DA 4A 49 42 17 1E 15 13 17 0D  /* 224 */
			29 01 00 00 00 00 15 B8 6D B0 48 4C 95 DA 33 69 12 7A DA 4B 49 42 17 1F 16 13 16 0D  /* 225 */
			29 01 00 00 00 00 15 B8 6D B0 48 4C 95 DA 33 69 12 7A DA 4B 49 43 18 20 15 13 16 0D  /* 226 */
			29 01 00 00 00 00 15 B8 6D B0 48 4C 95 DA 33 69 12 7A DA 4C 4A 43 17 1F 16 13 17 0D  /* 227 */
			29 01 00 00 00 00 15 B8 6D B0 48 4C 95 DA 33 69 12 7A DA 4C 4A 43 18 20 16 13 16 0D  /* 228 */
			29 01 00 00 00 00 15 B8 6D B0 48 4C 95 DA 33 69 12 7A DA 4D 4B 44 17 20 16 14 17 0D  /* 229 */
			29 01 00 00 00 00 15 B8 6D B0 48 4C 95 DA 33 69 12 7A DA 4D 4B 44 18 20 16 13 17 0E  /* 230 */
			29 01 00 00 00 00 15 B8 6D B0 48 4C 95 DA 33 69 12 7A DA 4D 4C 45 19 20 16 13 17 0D  /* 231 */
			29 01 00 00 00 00 15 B8 6D B0 48 4C 95 DA 33 69 12 7A DA 4E 4C 45 18 20 16 14 18 0E  /* 232 */
			29 01 00 00 00 00 15 B8 6D B0 48 4C 95 DA 33 69 12 7A DA 4E 4D 45 19 20 17 13 17 0D  /* 233 */
			29 01 00 00 00 00 15 B8 6D B0 48 4C 95 DA 33 69 12 7A DA 4F 4D 46 18 20 16 14 18 0E  /* 234 */
			29 01 00 00 00 00 15 B8 6D B0 48 4C 95 DA 33 69 12 7A DA 4F 4D 46 19 21 17 14 18 0D  /* 235 */
			29 01 00 00 00 00 15 B8 6D B0 48 4C 95 DA 33 69 12 7A DA 50 4E 46 18 21 17 14 17 0E  /* 236 */
			29 01 00 00 00 00 15 B8 6D B0 48 4C 95 DA 33 69 12 7A DA 50 4E 47 19 21 17 14 18 0D  /* 237 */
			29 01 00 00 00 00 15 B8 6D B0 48 4C 95 DA 33 69 12 7A DA 50 4E 47 19 21 17 14 18 0E  /* 238 */
			29 01 00 00 00 00 15 B8 6D B0 48 4C 95 DA 33 69 12 7A DA 51 4F 47 19 21 17 14 18 0E  /* 239 */
			29 01 00 00 00 00 15 B8 6D B0 48 4C 95 DA 33 69 12 7A DA 51 4F 48 19 22 17 15 18 0E  /* 240 */
			29 01 00 00 00 00 15 B8 6D B0 48 4C 95 DA 33 69 12 7A DA 51 50 48 1A 21 17 14 19 0E  /* 241 */
			29 01 00 00 00 00 15 B8 6D B0 48 4C 95 DA 33 69 12 7A DA 52 50 48 19 22 18 15 18 0E  /* 242 */
			29 01 00 00 00 00 15 B8 6D B0 48 4C 95 DA 33 69 12 7A DA 52 50 49 1A 22 17 15 19 0F  /* 243 */
			29 01 00 00 00 00 15 B8 6D B0 48 4C 95 DA 33 69 12 7A DA 53 51 49 19 22 18 15 19 0E  /* 244 */
			29 01 00 00 00 00 15 B8 6D B0 48 4C 95 DA 33 69 12 7A DA 53 51 4A 1A 23 17 15 18 0F  /* 245 */
			29 01 00 00 00 00 15 B8 6D B0 48 4C 95 DA 33 69 12 7A DA 53 52 4A 1A 22 18 15 19 0E  /* 246 */
			29 01 00 00 00 00 15 B8 6D B0 48 4C 95 DA 33 69 12 7A DA 54 52 4A 1A 23 18 15 19 0F  /* 247 */
			29 01 00 00 00 00 15 B8 6D B0 48 4C 95 DA 33 69 12 7A DA 55 53 4B 1A 23 18 15 19 0F  /* 248 */
			29 01 00 00 00 00 15 B8 6D B0 48 4C 95 DA 33 69 12 7A DA 55 53 4B 1A 23 19 16 1A 0E  /* 249 */
			29 01 00 00 00 00 15 B8 6D B0 48 4C 95 DA 33 69 12 7A DA 55 53 4C 1B 24 18 15 19 0F  /* 250 */
			29 01 00 00 00 00 15 B8 6D B0 48 4C 95 DA 33 69 12 7A DA 56 54 4C 1A 23 19 16 1A 0E  /* 251 */
			29 01 00 00 00 00 15 B8 6D B0 48 4C 95 DA 33 69 12 7A DA 56 54 4C 1B 24 19 15 19 0F  /* 252 */
			29 01 00 00 00 00 15 B8 6D B0 48 4C 95 DA 33 69 12 7A DA 56 54 4C 1B 24 19 16 1A 0F  /* 253 */
			29 01 00 00 00 00 15 B8 6D B0 48 4C 95 DA 33 69 12 7A DA 57 55 4D 1B 24 19 16 1A 0F  /* 254 */
			29 01 00 00 00 00 15 B8 6D B0 48 4C 95 DA 33 69 12 7A DA 57 55 4D 1B 24 19 16 1A 0F  /* 255 */
		];

		samsung,irc_subdivision_tx_cmds_revB = [
			29 01 00 00 00 00 15 B8 6D B0 48 4C 95 DA 33 69 12 7A DA 00 00 00 00 00 00 00 00 00  /* 00 */
			29 01 00 00 00 00 15 B8 6D B0 48 4C 95 DA 33 69 12 7A DA 00 00 00 00 00 00 00 00 00  /* 01 */
			29 01 00 00 00 00 15 B8 6D B0 48 4C 95 DA 33 69 12 7A DA 00 00 00 00 00 00 00 00 00  /* 02 */
			29 01 00 00 00 00 15 B8 6D B0 48 4C 95 DA 33 69 12 7A DA 00 00 00 00 00 00 00 00 00  /* 03 */
			29 01 00 00 00 00 15 B8 6D B0 48 4C 95 DA 33 69 12 7A DA 00 00 00 00 00 00 00 00 00  /* 04 */
			29 01 00 00 00 00 15 B8 6D B0 48 4C 95 DA 33 69 12 7A DA 00 00 00 00 00 00 00 00 00  /* 05 */
			29 01 00 00 00 00 15 B8 6D B0 48 4C 95 DA 33 69 12 7A DA 00 00 00 00 00 00 00 00 00  /* 06 */
			29 01 00 00 00 00 15 B8 6D B0 48 4C 95 DA 33 69 12 7A DA 00 00 00 00 00 00 00 00 00  /* 07 */
			29 01 00 00 00 00 15 B8 6D B0 48 4C 95 DA 33 69 12 7A DA 00 00 00 00 00 00 00 00 00  /* 08 */
			29 01 00 00 00 00 15 B8 6D B0 48 4C 95 DA 33 69 12 7A DA 00 00 00 00 00 00 00 00 00  /* 09 */
			29 01 00 00 00 00 15 B8 6D B0 48 4C 95 DA 33 69 12 7A DA 00 00 00 00 00 00 00 00 00  /* 10 */
			29 01 00 00 00 00 15 B8 6D B0 48 4C 95 DA 33 69 12 7A DA 00 00 00 00 00 00 00 00 00  /* 11 */
			29 01 00 00 00 00 15 B8 6D B0 48 4C 95 DA 33 69 12 7A DA 00 00 00 00 00 00 00 00 00  /* 12 */
			29 01 00 00 00 00 15 B8 6D B0 48 4C 95 DA 33 69 12 7A DA 00 00 00 00 00 00 00 00 00  /* 13 */
			29 01 00 00 00 00 15 B8 6D B0 48 4C 95 DA 33 69 12 7A DA 00 00 00 00 00 00 00 00 00  /* 14 */
			29 01 00 00 00 00 15 B8 6D B0 48 4C 95 DA 33 69 12 7A DA 00 00 00 00 00 00 00 00 00  /* 15 */
			29 01 00 00 00 00 15 B8 6D B0 48 4C 95 DA 33 69 12 7A DA 00 00 00 00 00 00 00 00 00  /* 16 */
			29 01 00 00 00 00 15 B8 6D B0 48 4C 95 DA 33 69 12 7A DA 00 00 00 00 00 00 00 00 00  /* 17 */
			29 01 00 00 00 00 15 B8 6D B0 48 4C 95 DA 33 69 12 7A DA 00 00 00 00 00 00 00 00 00  /* 18 */
			29 01 00 00 00 00 15 B8 6D B0 48 4C 95 DA 33 69 12 7A DA 00 00 00 00 00 00 00 00 00  /* 19 */
			29 01 00 00 00 00 15 B8 6D B0 48 4C 95 DA 33 69 12 7A DA 00 00 00 00 00 00 00 00 00  /* 20 */
			29 01 00 00 00 00 15 B8 6D B0 48 4C 95 DA 33 69 12 7A DA 00 00 00 00 00 00 00 00 00  /* 21 */
			29 01 00 00 00 00 15 B8 6D B0 48 4C 95 DA 33 69 12 7A DA 00 00 00 00 00 00 00 00 00  /* 22 */
			29 01 00 00 00 00 15 B8 6D B0 48 4C 95 DA 33 69 12 7A DA 00 00 00 00 00 00 00 00 00  /* 23 */
			29 01 00 00 00 00 15 B8 6D B0 48 4C 95 DA 33 69 12 7A DA 00 00 00 00 00 00 00 00 00  /* 24 */
			29 01 00 00 00 00 15 B8 6D B0 48 4C 95 DA 33 69 12 7A DA 00 00 00 00 00 00 00 00 00  /* 25 */
			29 01 00 00 00 00 15 B8 6D B0 48 4C 95 DA 33 69 12 7A DA 00 00 00 00 00 00 00 00 00  /* 26 */
			29 01 00 00 00 00 15 B8 6D B0 48 4C 95 DA 33 69 12 7A DA 00 00 00 00 00 00 00 00 00  /* 27 */
			29 01 00 00 00 00 15 B8 6D B0 48 4C 95 DA 33 69 12 7A DA 00 00 00 00 00 00 00 00 00  /* 28 */
			29 01 00 00 00 00 15 B8 6D B0 48 4C 95 DA 33 69 12 7A DA 00 00 00 00 00 00 00 00 00  /* 29 */
			29 01 00 00 00 00 15 B8 6D B0 48 4C 95 DA 33 69 12 7A DA 00 00 00 00 00 00 00 00 00  /* 30 */
			29 01 00 00 00 00 15 B8 6D B0 48 4C 95 DA 33 69 12 7A DA 00 00 00 00 00 00 00 00 00  /* 31 */
			29 01 00 00 00 00 15 B8 6D B0 48 4C 95 DA 33 69 12 7A DA 00 00 00 00 00 00 00 00 00  /* 32 */
			29 01 00 00 00 00 15 B8 6D B0 48 4C 95 DA 33 69 12 7A DA 00 00 00 00 00 00 00 00 00  /* 33 */
			29 01 00 00 00 00 15 B8 6D B0 48 4C 95 DA 33 69 12 7A DA 00 00 00 00 00 00 00 00 00  /* 34 */
			29 01 00 00 00 00 15 B8 6D B0 48 4C 95 DA 33 69 12 7A DA 00 00 00 00 00 00 00 00 00  /* 35 */
			29 01 00 00 00 00 15 B8 6D B0 48 4C 95 DA 33 69 12 7A DA 00 00 00 00 00 00 00 00 00  /* 36 */
			29 01 00 00 00 00 15 B8 6D B0 48 4C 95 DA 33 69 12 7A DA 00 00 00 00 00 00 00 00 00  /* 37 */
			29 01 00 00 00 00 15 B8 6D B0 48 4C 95 DA 33 69 12 7A DA 00 00 00 00 00 00 00 00 00  /* 38 */
			29 01 00 00 00 00 15 B8 6D B0 48 4C 95 DA 33 69 12 7A DA 02 02 02 01 01 01 01 00 01  /* 39 */
			29 01 00 00 00 00 15 B8 6D B0 48 4C 95 DA 33 69 12 7A DA 02 02 02 01 01 01 01 00 01  /* 40 */
			29 01 00 00 00 00 15 B8 6D B0 48 4C 95 DA 33 69 12 7A DA 02 02 02 01 01 01 01 01 01  /* 41 */
			29 01 00 00 00 00 15 B8 6D B0 48 4C 95 DA 33 69 12 7A DA 02 02 02 01 01 01 01 01 01  /* 42 */
			29 01 00 00 00 00 15 B8 6D B0 48 4C 95 DA 33 69 12 7A DA 02 02 02 01 01 01 01 01 01  /* 43 */
			29 01 00 00 00 00 15 B8 6D B0 48 4C 95 DA 33 69 12 7A DA 02 02 02 01 01 01 01 01 01  /* 44 */
			29 01 00 00 00 00 15 B8 6D B0 48 4C 95 DA 33 69 12 7A DA 03 03 02 01 01 02 01 00 01  /* 45 */
			29 01 00 00 00 00 15 B8 6D B0 48 4C 95 DA 33 69 12 7A DA 03 03 02 01 01 02 01 00 01  /* 46 */
			29 01 00 00 00 00 15 B8 6D B0 48 4C 95 DA 33 69 12 7A DA 03 03 03 01 01 01 01 01 01  /* 47 */
			29 01 00 00 00 00 15 B8 6D B0 48 4C 95 DA 33 69 12 7A DA 03 03 03 01 01 01 01 01 01  /* 48 */
			29 01 00 00 00 00 15 B8 6D B0 48 4C 95 DA 33 69 12 7A DA 03 03 03 01 01 01 01 01 01  /* 49 */
			29 01 00 00 00 00 15 B8 6D B0 48 4C 95 DA 33 69 12 7A DA 03 03 03 01 01 01 01 01 01  /* 50 */
			29 01 00 00 00 00 15 B8 6D B0 48 4C 95 DA 33 69 12 7A DA 03 03 03 02 02 02 01 00 01  /* 51 */
			29 01 00 00 00 00 15 B8 6D B0 48 4C 95 DA 33 69 12 7A DA 03 03 03 02 02 02 01 00 01  /* 52 */
			29 01 00 00 00 00 15 B8 6D B0 48 4C 95 DA 33 69 12 7A DA 04 03 03 01 02 02 01 01 01  /* 53 */
			29 01 00 00 00 00 15 B8 6D B0 48 4C 95 DA 33 69 12 7A DA 04 03 03 01 02 02 01 01 01  /* 54 */
			29 01 00 00 00 00 15 B8 6D B0 48 4C 95 DA 33 69 12 7A DA 04 04 03 01 01 02 01 01 01  /* 55 */
			29 01 00 00 00 00 15 B8 6D B0 48 4C 95 DA 33 69 12 7A DA 04 04 03 01 01 02 02 01 02  /* 56 */
			29 01 00 00 00 00 15 B8 6D B0 48 4C 95 DA 33 69 12 7A DA 04 04 04 02 02 02 01 01 01  /* 57 */
			29 01 00 00 00 00 15 B8 6D B0 48 4C 95 DA 33 69 12 7A DA 04 04 04 02 02 02 01 01 01  /* 58 */
			29 01 00 00 00 00 15 B8 6D B0 48 4C 95 DA 33 69 12 7A DA 04 04 04 02 02 02 01 01 01  /* 59 */
			29 01 00 00 00 00 15 B8 6D B0 48 4C 95 DA 33 69 12 7A DA 05 04 04 01 02 02 02 01 02  /* 60 */
			29 01 00 00 00 00 15 B8 6D B0 48 4C 95 DA 33 69 12 7A DA 05 04 04 01 02 02 02 01 02  /* 61 */
			29 01 00 00 00 00 15 B8 6D B0 48 4C 95 DA 33 69 12 7A DA 05 05 04 02 02 03 01 01 01  /* 62 */
			29 01 00 00 00 00 15 B8 6D B0 48 4C 95 DA 33 69 12 7A DA 05 05 04 02 02 03 01 01 02  /* 63 */
			29 01 00 00 00 00 15 B8 6D B0 48 4C 95 DA 33 69 12 7A DA 05 05 05 02 02 02 02 01 02  /* 64 */
			29 01 00 00 00 00 15 B8 6D B0 48 4C 95 DA 33 69 12 7A DA 05 05 05 02 02 02 02 01 02  /* 65 */
			29 01 00 00 00 00 15 B8 6D B0 48 4C 95 DA 33 69 12 7A DA 05 05 05 02 02 02 02 02 02  /* 66 */
			29 01 00 00 00 00 15 B8 6D B0 48 4C 95 DA 33 69 12 7A DA 06 05 05 02 03 03 02 01 02  /* 67 */
			29 01 00 00 00 00 15 B8 6D B0 48 4C 95 DA 33 69 12 7A DA 06 06 05 02 02 03 02 01 02  /* 68 */
			29 01 00 00 00 00 15 B8 6D B0 48 4C 95 DA 33 69 12 7A DA 06 06 05 02 02 03 02 02 02  /* 69 */
			29 01 00 00 00 00 15 B8 6D B0 48 4C 95 DA 33 69 12 7A DA 06 06 06 03 03 03 02 01 02  /* 70 */
			29 01 00 00 00 00 15 B8 6D B0 48 4C 95 DA 33 69 12 7A DA 06 06 06 03 03 03 02 01 02  /* 71 */
			29 01 00 00 00 00 15 B8 6D B0 48 4C 95 DA 33 69 12 7A DA 07 06 06 02 03 03 02 02 02  /* 72 */
			29 01 00 00 00 00 15 B8 6D B0 48 4C 95 DA 33 69 12 7A DA 07 07 06 03 03 04 02 01 02  /* 73 */
			29 01 00 00 00 00 15 B8 6D B0 48 4C 95 DA 33 69 12 7A DA 07 07 06 03 03 04 02 01 02  /* 74 */
			29 01 00 00 00 00 15 B8 6D B0 48 4C 95 DA 33 69 12 7A DA 07 07 07 03 03 03 03 02 03  /* 75 */
			29 01 00 00 00 00 15 B8 6D B0 48 4C 95 DA 33 69 12 7A DA 08 07 07 03 04 04 02 01 02  /* 76 */
			29 01 00 00 00 00 15 B8 6D B0 48 4C 95 DA 33 69 12 7A DA 08 08 07 03 03 04 02 01 02  /* 77 */
			29 01 00 00 00 00 15 B8 6D B0 48 4C 95 DA 33 69 12 7A DA 08 08 07 03 03 04 03 02 03  /* 78 */
			29 01 00 00 00 00 15 B8 6D B0 48 4C 95 DA 33 69 12 7A DA 08 08 07 04 04 05 02 01 02  /* 79 */
			29 01 00 00 00 00 15 B8 6D B0 48 4C 95 DA 33 69 12 7A DA 08 08 08 04 04 04 02 01 03  /* 80 */
			29 01 00 00 00 00 15 B8 6D B0 48 4C 95 DA 33 69 12 7A DA 09 09 08 03 03 04 03 02 03  /* 81 */
			29 01 00 00 00 00 15 B8 6D B0 48 4C 95 DA 33 69 12 7A DA 09 09 08 04 04 05 03 01 03  /* 82 */
			29 01 00 00 00 00 15 B8 6D B0 48 4C 95 DA 33 69 12 7A DA 0A 09 08 03 04 05 03 02 03  /* 83 */
			29 01 00 00 00 00 15 B8 6D B0 48 4C 95 DA 33 69 12 7A DA 0A 0A 09 04 04 05 03 01 03  /* 84 */
			29 01 00 00 00 00 15 B8 6D B0 48 4C 95 DA 33 69 12 7A DA 0A 0A 09 04 04 05 03 02 03  /* 85 */
			29 01 00 00 00 00 15 B8 6D B0 48 4C 95 DA 33 69 12 7A DA 0A 0A 09 04 04 05 04 02 04  /* 86 */
			29 01 00 00 00 00 15 B8 6D B0 48 4C 95 DA 33 69 12 7A DA 0B 0B 0A 04 04 05 03 02 03  /* 87 */
			29 01 00 00 00 00 15 B8 6D B0 48 4C 95 DA 33 69 12 7A DA 0B 0B 0A 04 04 05 04 02 04  /* 88 */
			29 01 00 00 00 00 15 B8 6D B0 48 4C 95 DA 33 69 12 7A DA 0B 0B 0A 05 05 06 03 02 04  /* 89 */
			29 01 00 00 00 00 15 B8 6D B0 48 4C 95 DA 33 69 12 7A DA 0C 0B 0A 04 05 06 04 02 04  /* 90 */
			29 01 00 00 00 00 15 B8 6D B0 48 4C 95 DA 33 69 12 7A DA 0C 0C 0B 05 05 06 03 02 04  /* 91 */
			29 01 00 00 00 00 15 B8 6D B0 48 4C 95 DA 33 69 12 7A DA 0C 0C 0B 05 05 06 04 03 04  /* 92 */
			29 01 00 00 00 00 15 B8 6D B0 48 4C 95 DA 33 69 12 7A DA 0D 0D 0B 05 05 07 04 02 04  /* 93 */
			29 01 00 00 00 00 15 B8 6D B0 48 4C 95 DA 33 69 12 7A DA 0D 0D 0C 05 05 06 05 03 05  /* 94 */
			29 01 00 00 00 00 15 B8 6D B0 48 4C 95 DA 33 69 12 7A DA 0E 0D 0C 05 06 07 04 03 04  /* 95 */
			29 01 00 00 00 00 15 B8 6D B0 48 4C 95 DA 33 69 12 7A DA 0E 0E 0C 06 06 08 04 02 04  /* 96 */
			29 01 00 00 00 00 15 B8 6D B0 48 4C 95 DA 33 69 12 7A DA 0F 0E 0D 05 06 07 05 03 05  /* 97 */
			29 01 00 00 00 00 15 B8 6D B0 48 4C 95 DA 33 69 12 7A DA 0F 0F 0D 06 06 08 04 03 05  /* 98 */
			29 01 00 00 00 00 15 B8 6D B0 48 4C 95 DA 33 69 12 7A DA 10 0F 0E 06 07 08 04 03 05  /* 99 */
			29 01 00 00 00 00 15 B8 6D B0 48 4C 95 DA 33 69 12 7A DA 10 10 0E 06 06 08 05 03 05  /* 100 */
			29 01 00 00 00 00 15 B8 6D B0 48 4C 95 DA 33 69 12 7A DA 11 10 0F 06 07 08 05 03 05  /* 101 */
			29 01 00 00 00 00 15 B8 6D B0 48 4C 95 DA 33 69 12 7A DA 11 11 0F 07 07 09 05 03 05  /* 102 */
			29 01 00 00 00 00 15 B8 6D B0 48 4C 95 DA 33 69 12 7A DA 12 11 10 06 07 08 06 04 06  /* 103 */
			29 01 00 00 00 00 15 B8 6D B0 48 4C 95 DA 33 69 12 7A DA 12 12 10 07 07 09 06 04 06  /* 104 */
			29 01 00 00 00 00 15 B8 6D B0 48 4C 95 DA 33 69 12 7A DA 13 12 11 07 08 09 06 04 06  /* 105 */
			29 01 00 00 00 00 15 B8 6D B0 48 4C 95 DA 33 69 12 7A DA 13 13 11 08 08 0A 06 04 06  /* 106 */
			29 01 00 00 00 00 15 B8 6D B0 48 4C 95 DA 33 69 12 7A DA 14 13 12 08 09 0A 06 04 06  /* 107 */
			29 01 00 00 00 00 15 B8 6D B0 48 4C 95 DA 33 69 12 7A DA 14 14 12 08 08 0A 07 04 07  /* 108 */
			29 01 00 00 00 00 15 B8 6D B0 48 4C 95 DA 33 69 12 7A DA 15 15 13 08 08 0A 07 05 07  /* 109 */
			29 01 00 00 00 00 15 B8 6D B0 48 4C 95 DA 33 69 12 7A DA 16 15 13 08 09 0B 07 05 07  /* 110 */
			29 01 00 00 00 00 15 B8 6D B0 48 4C 95 DA 33 69 12 7A DA 16 16 14 09 09 0B 07 04 07  /* 111 */
			29 01 00 00 00 00 15 B8 6D B0 48 4C 95 DA 33 69 12 7A DA 17 16 14 09 0A 0C 07 04 07  /* 112 */
			29 01 00 00 00 00 15 B8 6D B0 48 4C 95 DA 33 69 12 7A DA 18 17 15 09 0A 0C 08 05 08  /* 113 */
			29 01 00 00 00 00 15 B8 6D B0 48 4C 95 DA 33 69 12 7A DA 19 18 16 09 0A 0C 08 05 08  /* 114 */
			29 01 00 00 00 00 15 B8 6D B0 48 4C 95 DA 33 69 12 7A DA 19 19 17 0A 0A 0C 08 05 09  /* 115 */
			29 01 00 00 00 00 15 B8 6D B0 48 4C 95 DA 33 69 12 7A DA 1A 1A 17 0A 0A 0D 08 05 09  /* 116 */
			29 01 00 00 00 00 15 B8 6D B0 48 4C 95 DA 33 69 12 7A DA 1B 1A 18 0A 0B 0D 09 06 09  /* 117 */
			29 01 00 00 00 00 15 B8 6D B0 48 4C 95 DA 33 69 12 7A DA 1C 1B 19 0B 0C 0E 08 05 09  /* 118 */
			29 01 00 00 00 00 15 B8 6D B0 48 4C 95 DA 33 69 12 7A DA 1D 1C 19 0B 0C 0F 09 06 09  /* 119 */
			29 01 00 00 00 00 15 B8 6D B0 48 4C 95 DA 33 69 12 7A DA 1E 1D 1A 0B 0C 0F 09 06 0A  /* 120 */
			29 01 00 00 00 00 15 B8 6D B0 48 4C 95 DA 33 69 12 7A DA 1F 1E 1B 0C 0D 10 09 06 0A  /* 121 */
			29 01 00 00 00 00 15 B8 6D B0 48 4C 95 DA 33 69 12 7A DA 1F 1F 1C 0D 0D 10 0A 06 0A  /* 122 */
			29 01 00 00 00 00 15 B8 6D B0 48 4C 95 DA 33 69 12 7A DA 21 20 1D 0C 0D 10 0A 07 0B  /* 123 */
			29 01 00 00 00 00 15 B8 6D B0 48 4C 95 DA 33 69 12 7A DA 22 21 1E 0D 0E 11 0A 06 0A  /* 124 */
			29 01 00 00 00 00 15 B8 6D B0 48 4C 95 DA 33 69 12 7A DA 23 22 1F 0D 0E 11 0B 07 0B  /* 125 */
			29 01 00 00 00 00 15 B8 6D B0 48 4C 95 DA 33 69 12 7A DA 24 23 20 0E 0F 12 0B 07 0B  /* 126 */
			29 01 00 00 00 00 15 B8 6D B0 48 4C 95 DA 33 69 12 7A DA 25 24 21 0E 0F 12 0C 07 0C  /* 127 */
			29 01 00 00 00 00 15 B8 6D B0 48 4C 95 DA 33 69 12 7A DA 26 25 22 0F 10 13 0B 07 0C  /* 128 */
			29 01 00 00 00 00 15 B8 6D B0 48 4C 95 DA 33 69 12 7A DA 26 25 22 0F 10 13 0C 08 0D  /* 129 */
			29 01 00 00 00 00 15 B8 6D B0 48 4C 95 DA 33 69 12 7A DA 27 26 22 0F 10 14 0C 07 0C  /* 130 */
			29 01 00 00 00 00 15 B8 6D B0 48 4C 95 DA 33 69 12 7A DA 27 26 22 0F 10 14 0C 08 0D  /* 131 */
			29 01 00 00 00 00 15 B8 6D B0 48 4C 95 DA 33 69 12 7A DA 27 26 23 10 11 14 0C 07 0C  /* 132 */
			29 01 00 00 00 00 15 B8 6D B0 48 4C 95 DA 33 69 12 7A DA 28 27 23 0F 10 14 0D 08 0D  /* 133 */
			29 01 00 00 00 00 15 B8 6D B0 48 4C 95 DA 33 69 12 7A DA 28 27 23 10 11 15 0C 07 0C  /* 134 */
			29 01 00 00 00 00 15 B8 6D B0 48 4C 95 DA 33 69 12 7A DA 28 27 24 10 11 14 0D 08 0D  /* 135 */
			29 01 00 00 00 00 15 B8 6D B0 48 4C 95 DA 33 69 12 7A DA 29 28 24 10 11 15 0C 08 0D  /* 136 */
			29 01 00 00 00 00 15 B8 6D B0 48 4C 95 DA 33 69 12 7A DA 29 28 24 10 11 15 0D 08 0D  /* 137 */
			29 01 00 00 00 00 15 B8 6D B0 48 4C 95 DA 33 69 12 7A DA 29 28 25 11 12 15 0C 08 0D  /* 138 */
			29 01 00 00 00 00 15 B8 6D B0 48 4C 95 DA 33 69 12 7A DA 2A 29 25 10 11 15 0D 08 0E  /* 139 */
			29 01 00 00 00 00 15 B8 6D B0 48 4C 95 DA 33 69 12 7A DA 2A 29 25 11 12 16 0D 08 0D  /* 140 */
			29 01 00 00 00 00 15 B8 6D B0 48 4C 95 DA 33 69 12 7A DA 2A 29 26 11 12 15 0D 08 0E  /* 141 */
			29 01 00 00 00 00 15 B8 6D B0 48 4C 95 DA 33 69 12 7A DA 2B 2A 26 11 12 16 0D 08 0D  /* 142 */
			29 01 00 00 00 00 15 B8 6D B0 48 4C 95 DA 33 69 12 7A DA 2B 2A 26 11 12 16 0E 09 0E  /* 143 */
			29 01 00 00 00 00 15 B8 6D B0 48 4C 95 DA 33 69 12 7A DA 2C 2B 27 11 12 16 0D 08 0E  /* 144 */
			29 01 00 00 00 00 15 B8 6D B0 48 4C 95 DA 33 69 12 7A DA 2C 2B 27 11 12 16 0E 09 0F  /* 145 */
			29 01 00 00 00 00 15 B8 6D B0 48 4C 95 DA 33 69 12 7A DA 2C 2B 27 12 13 17 0D 08 0E  /* 146 */
			29 01 00 00 00 00 15 B8 6D B0 48 4C 95 DA 33 69 12 7A DA 2D 2C 28 11 12 16 0E 09 0F  /* 147 */
			29 01 00 00 00 00 15 B8 6D B0 48 4C 95 DA 33 69 12 7A DA 2D 2C 28 12 13 17 0E 09 0E  /* 148 */
			29 01 00 00 00 00 15 B8 6D B0 48 4C 95 DA 33 69 12 7A DA 2E 2D 28 11 12 17 0F 09 0F  /* 149 */
			29 01 00 00 00 00 15 B8 6D B0 48 4C 95 DA 33 69 12 7A DA 2E 2D 29 12 13 17 0E 09 0F  /* 150 */
			29 01 00 00 00 00 15 B8 6D B0 48 4C 95 DA 33 69 12 7A DA 2E 2D 29 13 14 18 0E 09 0E  /* 151 */
			29 01 00 00 00 00 15 B8 6D B0 48 4C 95 DA 33 69 12 7A DA 2F 2E 29 12 13 18 0E 09 0F  /* 152 */
			29 01 00 00 00 00 15 B8 6D B0 48 4C 95 DA 33 69 12 7A DA 2F 2E 2A 12 13 17 0F 0A 10  /* 153 */
			29 01 00 00 00 00 15 B8 6D B0 48 4C 95 DA 33 69 12 7A DA 2F 2E 2A 13 14 18 0F 09 0F  /* 154 */
			29 01 00 00 00 00 15 B8 6D B0 48 4C 95 DA 33 69 12 7A DA 30 2F 2A 13 14 19 0E 09 0F  /* 155 */
			29 01 00 00 00 00 15 B8 6D B0 48 4C 95 DA 33 69 12 7A DA 30 2F 2B 13 14 18 0F 09 0F  /* 156 */
			29 01 00 00 00 00 15 B8 6D B0 48 4C 95 DA 33 69 12 7A DA 30 2F 2B 13 14 18 0F 0A 10  /* 157 */
			29 01 00 00 00 00 15 B8 6D B0 48 4C 95 DA 33 69 12 7A DA 31 30 2B 13 14 19 0F 0A 10  /* 158 */
			29 01 00 00 00 00 15 B8 6D B0 48 4C 95 DA 33 69 12 7A DA 31 30 2C 14 15 19 0F 09 0F  /* 159 */
			29 01 00 00 00 00 15 B8 6D B0 48 4C 95 DA 33 69 12 7A DA 32 31 2C 13 14 19 10 0A 10  /* 160 */
			29 01 00 00 00 00 15 B8 6D B0 48 4C 95 DA 33 69 12 7A DA 32 31 2C 14 15 1A 0F 0A 10  /* 161 */
			29 01 00 00 00 00 15 B8 6D B0 48 4C 95 DA 33 69 12 7A DA 32 31 2D 14 15 19 10 0A 10  /* 162 */
			29 01 00 00 00 00 15 B8 6D B0 48 4C 95 DA 33 69 12 7A DA 33 32 2D 14 15 1A 0F 0A 10  /* 163 */
			29 01 00 00 00 00 15 B8 6D B0 48 4C 95 DA 33 69 12 7A DA 33 32 2D 14 15 1A 10 0A 11  /* 164 */
			29 01 00 00 00 00 15 B8 6D B0 48 4C 95 DA 33 69 12 7A DA 34 32 2E 14 16 1A 10 0A 10  /* 165 */
			29 01 00 00 00 00 15 B8 6D B0 48 4C 95 DA 33 69 12 7A DA 34 33 2E 14 15 1A 10 0A 11  /* 166 */
			29 01 00 00 00 00 15 B8 6D B0 48 4C 95 DA 33 69 12 7A DA 34 33 2E 15 16 1B 10 0A 11  /* 167 */
			29 01 00 00 00 00 15 B8 6D B0 48 4C 95 DA 33 69 12 7A DA 35 33 2F 14 16 1A 11 0A 11  /* 168 */
			29 01 00 00 00 00 15 B8 6D B0 48 4C 95 DA 33 69 12 7A DA 35 34 2F 15 16 1B 10 0A 11  /* 169 */
			29 01 00 00 00 00 15 B8 6D B0 48 4C 95 DA 33 69 12 7A DA 35 34 2F 15 16 1B 11 0B 12  /* 170 */
			29 01 00 00 00 00 15 B8 6D B0 48 4C 95 DA 33 69 12 7A DA 36 35 30 15 16 1B 11 0A 11  /* 171 */
			29 01 00 00 00 00 15 B8 6D B0 48 4C 95 DA 33 69 12 7A DA 36 35 30 15 16 1B 11 0B 12  /* 172 */
			29 01 00 00 00 00 15 B8 6D B0 48 4C 95 DA 33 69 12 7A DA 36 35 30 16 17 1C 11 0A 11  /* 173 */
			29 01 00 00 00 00 15 B8 6D B0 48 4C 95 DA 33 69 12 7A DA 37 36 31 15 16 1B 11 0B 12  /* 174 */
			29 01 00 00 00 00 15 B8 6D B0 48 4C 95 DA 33 69 12 7A DA 37 36 31 16 17 1C 11 0B 12  /* 175 */
			29 01 00 00 00 00 15 B8 6D B0 48 4C 95 DA 33 69 12 7A DA 38 36 31 15 17 1C 12 0B 12  /* 176 */
			29 01 00 00 00 00 15 B8 6D B0 48 4C 95 DA 33 69 12 7A DA 38 37 32 16 17 1C 11 0B 12  /* 177 */
			29 01 00 00 00 00 15 B8 6D B0 48 4C 95 DA 33 69 12 7A DA 39 37 32 16 18 1D 11 0B 12  /* 178 */
			29 01 00 00 00 00 15 B8 6D B0 48 4C 95 DA 33 69 12 7A DA 39 37 32 16 18 1D 12 0B 12  /* 179 */
			29 01 00 00 00 00 15 B8 6D B0 48 4C 95 DA 33 69 12 7A DA 39 38 33 17 18 1D 11 0B 12  /* 180 */
			29 01 00 00 00 00 15 B8 6D B0 48 4C 95 DA 33 69 12 7A DA 3A 38 33 16 18 1D 12 0B 13  /* 181 */
			29 01 00 00 00 00 15 B8 6D B0 48 4C 95 DA 33 69 12 7A DA 3A 39 33 17 18 1E 12 0B 12  /* 182 */
			29 01 00 00 00 00 15 B8 6D B0 48 4C 95 DA 33 69 12 7A DA 3A 39 34 17 18 1D 12 0C 13  /* 183 */
			29 01 00 00 00 00 15 B8 6D B0 48 4C 95 DA 33 69 12 7A DA 3B 39 34 17 19 1E 12 0B 13  /* 184 */
			29 01 00 00 00 00 15 B8 6D B0 48 4C 95 DA 33 69 12 7A DA 3B 3A 34 17 18 1E 13 0C 13  /* 185 */
			29 01 00 00 00 00 15 B8 6D B0 48 4C 95 DA 33 69 12 7A DA 3B 3A 35 18 19 1E 12 0B 13  /* 186 */
			29 01 00 00 00 00 15 B8 6D B0 48 4C 95 DA 33 69 12 7A DA 3C 3A 35 17 19 1E 13 0C 14  /* 187 */
			29 01 00 00 00 00 15 B8 6D B0 48 4C 95 DA 33 69 12 7A DA 3C 3B 35 18 19 1F 13 0C 13  /* 188 */
			29 01 00 00 00 00 15 B8 6D B0 48 4C 95 DA 33 69 12 7A DA 3D 3B 36 17 19 1E 13 0C 14  /* 189 */
			29 01 00 00 00 00 15 B8 6D B0 48 4C 95 DA 33 69 12 7A DA 3D 3C 36 18 19 1F 13 0C 14  /* 190 */
			29 01 00 00 00 00 15 B8 6D B0 48 4C 95 DA 33 69 12 7A DA 3D 3C 36 18 19 1F 13 0C 14  /* 191 */
			29 01 00 00 00 00 15 B8 6D B0 48 4C 95 DA 33 69 12 7A DA 3E 3C 37 18 1A 1F 13 0C 14  /* 192 */
			29 01 00 00 00 00 15 B8 6D B0 48 4C 95 DA 33 69 12 7A DA 3E 3D 37 18 19 1F 14 0D 14  /* 193 */
			29 01 00 00 00 00 15 B8 6D B0 48 4C 95 DA 33 69 12 7A DA 3F 3D 37 18 1A 20 13 0C 14  /* 194 */
			29 01 00 00 00 00 15 B8 6D B0 48 4C 95 DA 33 69 12 7A DA 3F 3E 38 19 1A 20 13 0C 14  /* 195 */
			29 01 00 00 00 00 15 B8 6D B0 48 4C 95 DA 33 69 12 7A DA 3F 3E 38 19 1A 20 14 0D 15  /* 196 */
			29 01 00 00 00 00 15 B8 6D B0 48 4C 95 DA 33 69 12 7A DA 40 3E 38 19 1B 21 14 0C 14  /* 197 */
			29 01 00 00 00 00 15 B8 6D B0 48 4C 95 DA 33 69 12 7A DA 40 3F 39 19 1A 20 14 0D 15  /* 198 */
			29 01 00 00 00 00 15 B8 6D B0 48 4C 95 DA 33 69 12 7A DA 41 3F 39 19 1B 21 14 0D 15  /* 199 */
			29 01 00 00 00 00 15 B8 6D B0 48 4C 95 DA 33 69 12 7A DA 41 40 3A 19 1A 20 15 0D 15  /* 200 */
			29 01 00 00 00 00 15 B8 6D B0 48 4C 95 DA 33 69 12 7A DA 41 40 3A 1A 1B 21 14 0D 15  /* 201 */
			29 01 00 00 00 00 15 B8 6D B0 48 4C 95 DA 33 69 12 7A DA 42 40 3A 1A 1C 22 14 0C 15  /* 202 */
			29 01 00 00 00 00 15 B8 6D B0 48 4C 95 DA 33 69 12 7A DA 42 41 3B 1A 1B 21 15 0D 16  /* 203 */
			29 01 00 00 00 00 15 B8 6D B0 48 4C 95 DA 33 69 12 7A DA 43 41 3B 1A 1C 22 14 0D 15  /* 204 */
			29 01 00 00 00 00 15 B8 6D B0 48 4C 95 DA 33 69 12 7A DA 43 42 3B 1A 1B 22 15 0D 16  /* 205 */
			29 01 00 00 00 00 15 B8 6D B0 48 4C 95 DA 33 69 12 7A DA 43 42 3C 1B 1C 22 15 0D 15  /* 206 */
			29 01 00 00 00 00 15 B8 6D B0 48 4C 95 DA 33 69 12 7A DA 44 42 3C 1A 1C 22 15 0D 16  /* 207 */
			29 01 00 00 00 00 15 B8 6D B0 48 4C 95 DA 33 69 12 7A DA 44 43 3C 1B 1C 23 15 0D 16  /* 208 */
			29 01 00 00 00 00 15 B8 6D B0 48 4C 95 DA 33 69 12 7A DA 45 43 3D 1A 1C 22 16 0E 16  /* 209 */
			29 01 00 00 00 00 15 B8 6D B0 48 4C 95 DA 33 69 12 7A DA 45 43 3D 1B 1D 23 15 0D 16  /* 210 */
			29 01 00 00 00 00 15 B8 6D B0 48 4C 95 DA 33 69 12 7A DA 45 44 3D 1C 1D 24 15 0D 16  /* 211 */
			29 01 00 00 00 00 15 B8 6D B0 48 4C 95 DA 33 69 12 7A DA 46 44 3E 1B 1D 23 16 0E 17  /* 212 */
			29 01 00 00 00 00 15 B8 6D B0 48 4C 95 DA 33 69 12 7A DA 46 45 3E 1C 1D 24 15 0D 16  /* 213 */
			29 01 00 00 00 00 15 B8 6D B0 48 4C 95 DA 33 69 12 7A DA 47 45 3F 1B 1D 23 16 0E 17  /* 214 */
			29 01 00 00 00 00 15 B8 6D B0 48 4C 95 DA 33 69 12 7A DA 47 45 3F 1C 1E 24 16 0D 16  /* 215 */
			29 01 00 00 00 00 15 B8 6D B0 48 4C 95 DA 33 69 12 7A DA 47 46 3F 1C 1D 24 16 0E 17  /* 216 */
			29 01 00 00 00 00 15 B8 6D B0 48 4C 95 DA 33 69 12 7A DA 48 46 3F 1C 1E 25 16 0E 17  /* 217 */
			29 01 00 00 00 00 15 B8 6D B0 48 4C 95 DA 33 69 12 7A DA 48 46 40 1C 1E 24 17 0E 17  /* 218 */
			29 01 00 00 00 00 15 B8 6D B0 48 4C 95 DA 33 69 12 7A DA 49 47 40 1C 1E 25 16 0E 17  /* 219 */
			29 01 00 00 00 00 15 B8 6D B0 48 4C 95 DA 33 69 12 7A DA 49 47 41 1C 1E 24 17 0F 18  /* 220 */
			29 01 00 00 00 00 15 B8 6D B0 48 4C 95 DA 33 69 12 7A DA 49 48 41 1D 1E 25 17 0E 18  /* 221 */
			29 01 00 00 00 00 15 B8 6D B0 48 4C 95 DA 33 69 12 7A DA 4A 48 41 1C 1E 25 17 0F 18  /* 222 */
			29 01 00 00 00 00 15 B8 6D B0 48 4C 95 DA 33 69 12 7A DA 4A 48 41 1D 1F 26 17 0E 18  /* 223 */
			29 01 00 00 00 00 15 B8 6D B0 48 4C 95 DA 33 69 12 7A DA 4A 49 42 1D 1E 25 18 0F 18  /* 224 */
			29 01 00 00 00 00 15 B8 6D B0 48 4C 95 DA 33 69 12 7A DA 4B 49 42 1D 1F 26 17 0F 18  /* 225 */
			29 01 00 00 00 00 15 B8 6D B0 48 4C 95 DA 33 69 12 7A DA 4B 49 43 1E 20 26 17 0E 18  /* 226 */
			29 01 00 00 00 00 15 B8 6D B0 48 4C 95 DA 33 69 12 7A DA 4C 4A 43 1D 1F 26 18 0F 18  /* 227 */
			29 01 00 00 00 00 15 B8 6D B0 48 4C 95 DA 33 69 12 7A DA 4C 4A 43 1E 20 27 17 0F 18  /* 228 */
			29 01 00 00 00 00 15 B8 6D B0 48 4C 95 DA 33 69 12 7A DA 4D 4B 44 1E 20 27 17 0F 18  /* 229 */
			29 01 00 00 00 00 15 B8 6D B0 48 4C 95 DA 33 69 12 7A DA 4D 4B 44 1E 20 27 18 0F 19  /* 230 */
			29 01 00 00 00 00 15 B8 6D B0 48 4C 95 DA 33 69 12 7A DA 4D 4C 45 1F 20 27 18 0F 19  /* 231 */
			29 01 00 00 00 00 15 B8 6D B0 48 4C 95 DA 33 69 12 7A DA 4E 4C 45 1E 20 27 18 10 19  /* 232 */
			29 01 00 00 00 00 15 B8 6D B0 48 4C 95 DA 33 69 12 7A DA 4E 4D 45 1F 20 28 18 0F 19  /* 233 */
			29 01 00 00 00 00 15 B8 6D B0 48 4C 95 DA 33 69 12 7A DA 4F 4D 46 1E 20 27 19 10 1A  /* 234 */
			29 01 00 00 00 00 15 B8 6D B0 48 4C 95 DA 33 69 12 7A DA 4F 4D 46 1F 21 28 19 10 1A  /* 235 */
			29 01 00 00 00 00 15 B8 6D B0 48 4C 95 DA 33 69 12 7A DA 50 4E 46 1F 21 29 18 0F 19  /* 236 */
			29 01 00 00 00 00 15 B8 6D B0 48 4C 95 DA 33 69 12 7A DA 50 4E 47 1F 21 28 19 10 1A  /* 237 */
			29 01 00 00 00 00 15 B8 6D B0 48 4C 95 DA 33 69 12 7A DA 50 4E 47 1F 21 28 19 10 1A  /* 238 */
			29 01 00 00 00 00 15 B8 6D B0 48 4C 95 DA 33 69 12 7A DA 51 4F 47 1F 21 29 19 10 1A  /* 239 */
			29 01 00 00 00 00 15 B8 6D B0 48 4C 95 DA 33 69 12 7A DA 51 4F 48 20 22 29 19 0F 1A  /* 240 */
			29 01 00 00 00 00 15 B8 6D B0 48 4C 95 DA 33 69 12 7A DA 51 50 48 20 21 29 19 10 1A  /* 241 */
			29 01 00 00 00 00 15 B8 6D B0 48 4C 95 DA 33 69 12 7A DA 52 50 48 20 22 2A 19 10 1A  /* 242 */
			29 01 00 00 00 00 15 B8 6D B0 48 4C 95 DA 33 69 12 7A DA 52 50 49 20 22 29 1A 10 1B  /* 243 */
			29 01 00 00 00 00 15 B8 6D B0 48 4C 95 DA 33 69 12 7A DA 53 51 49 20 22 2A 1A 10 1B  /* 244 */
			29 01 00 00 00 00 15 B8 6D B0 48 4C 95 DA 33 69 12 7A DA 53 51 4A 21 23 2A 19 10 1A  /* 245 */
			29 01 00 00 00 00 15 B8 6D B0 48 4C 95 DA 33 69 12 7A DA 53 52 4A 21 22 2A 1A 10 1B  /* 246 */
			29 01 00 00 00 00 15 B8 6D B0 48 4C 95 DA 33 69 12 7A DA 54 52 4A 21 23 2B 1A 10 1B  /* 247 */
			29 01 00 00 00 00 15 B8 6D B0 48 4C 95 DA 33 69 12 7A DA 55 53 4B 21 23 2B 1A 10 1B  /* 248 */
			29 01 00 00 00 00 15 B8 6D B0 48 4C 95 DA 33 69 12 7A DA 55 53 4B 21 23 2B 1A 11 1B  /* 249 */
			29 01 00 00 00 00 15 B8 6D B0 48 4C 95 DA 33 69 12 7A DA 55 53 4C 22 24 2B 1A 10 1B  /* 250 */
			29 01 00 00 00 00 15 B8 6D B0 48 4C 95 DA 33 69 12 7A DA 56 54 4C 21 23 2B 1B 11 1C  /* 251 */
			29 01 00 00 00 00 15 B8 6D B0 48 4C 95 DA 33 69 12 7A DA 56 54 4C 22 24 2C 1A 10 1B  /* 252 */
			29 01 00 00 00 00 15 B8 6D B0 48 4C 95 DA 33 69 12 7A DA 56 54 4C 22 24 2C 1B 11 1C  /* 253 */
			29 01 00 00 00 00 15 B8 6D B0 48 4C 95 DA 33 69 12 7A DA 57 55 4D 22 24 2C 1B 11 1C  /* 254 */
			29 01 00 00 00 00 15 B8 6D B0 48 4C 95 DA 33 69 12 7A DA 57 55 4D 22 24 2C 1B 11 1C  /* 255 */
		];

		/*
		* ************************************************************************************************************************
		*  H/W Cursor
		* ************************************************************************************************************************
		*/

		samsung,hw_cursor_tx_cmds_revA = [
			29 01 00 00 00 00 0F E4 00 01 00 04 00 00 05 00 66 00 00 00 3C 1E
		];

		/*
		* ************************************************************************************************************************
		*  MCD
		* ************************************************************************************************************************
		*/

		samsung,mcd_on_tx_cmds_revA = [
			29 01 00 00 00 00 03 F0 5A 5A
			29 01 00 00 00 00 03 FC 5A 5A

			29 00 00 00 00 00 02 B0 03
			29 00 00 00 00 00 02 BB 39
			29 00 00 00 00 00 02 B0 14
			29 00 00 00 00 00 03 CB BF 1A
			29 00 00 00 00 00 02 B0 21
			29 00 00 00 00 00 05 CB D7 16 C4 D6
			29 00 00 00 00 00 02 B0 30
			29 00 00 00 64 00 02 CB D6

			29 01 00 00 00 00 3C		/* dummy for single transmission more 100ns delay */
			00 00 00 00 00 00 00 00 00 00
			00 00 00 00 00 00 00 00 00 00
			00 00 00 00 00 00 00 00 00 00
			00 00 00 00 00 00 00 00 00 00
			00 00 00 00 00 00 00 00 00 00
			00 00 00 00 00 00 00 00 00 00

			29 00 00 00 00 00 02 B0 06
			29 00 00 00 64 00 02 F6 13

			29 01 00 00 00 00 3C		/* dummy for single transmission more 100ns delay */
			00 00 00 00 00 00 00 00 00 00
			00 00 00 00 00 00 00 00 00 00
			00 00 00 00 00 00 00 00 00 00
			00 00 00 00 00 00 00 00 00 00
			00 00 00 00 00 00 00 00 00 00
			00 00 00 00 00 00 00 00 00 00

			29 00 00 00 64 00 02 F7 03

			29 01 00 00 00 00 3C		/* dummy for single transmission more 100ns delay */
			00 00 00 00 00 00 00 00 00 00
			00 00 00 00 00 00 00 00 00 00
			00 00 00 00 00 00 00 00 00 00
			00 00 00 00 00 00 00 00 00 00
			00 00 00 00 00 00 00 00 00 00
			00 00 00 00 00 00 00 00 00 00

			29 01 00 00 00 00 03 F0 A5 A5
			29 01 00 00 00 00 03 FC A5 A5
		];

		samsung,mcd_off_tx_cmds_revA = [
			29 01 00 00 00 00 03 F0 5A 5A
			29 01 00 00 00 00 03 FC 5A 5A

			29 00 00 00 00 00 02 B0 03
			29 00 00 00 00 00 02 BB 09
			29 00 00 00 00 00 02 B0 14
			29 00 00 00 00 00 03 CB 12 9B
			29 00 00 00 00 00 02 B0 21
			29 00 00 00 00 00 05 CB B0 00 00 C0
			29 00 00 00 00 00 02 B0 30
			29 00 00 00 64 00 02 CB C0

			29 01 00 00 00 00 3C		/* dummy for single transmission more 100ns delay */
			00 00 00 00 00 00 00 00 00 00
			00 00 00 00 00 00 00 00 00 00
			00 00 00 00 00 00 00 00 00 00
			00 00 00 00 00 00 00 00 00 00
			00 00 00 00 00 00 00 00 00 00
			00 00 00 00 00 00 00 00 00 00

			29 00 00 00 00 00 02 B0 06
			29 00 00 00 64 00 02 F6 BD

			29 01 00 00 00 00 3C		/* dummy for single transmission more 100ns delay */
			00 00 00 00 00 00 00 00 00 00
			00 00 00 00 00 00 00 00 00 00
			00 00 00 00 00 00 00 00 00 00
			00 00 00 00 00 00 00 00 00 00
			00 00 00 00 00 00 00 00 00 00
			00 00 00 00 00 00 00 00 00 00

			29 00 00 00 64 00 02 F7 03

			29 01 00 00 00 00 3C		/* dummy for single transmission more 100ns delay */
			00 00 00 00 00 00 00 00 00 00
			00 00 00 00 00 00 00 00 00 00
			00 00 00 00 00 00 00 00 00 00
			00 00 00 00 00 00 00 00 00 00
			00 00 00 00 00 00 00 00 00 00
			00 00 00 00 00 00 00 00 00 00

			29 01 00 00 00 00 03 F0 A5 A5
			29 01 00 00 00 00 03 FC A5 A5
		];

		/*
		* ************************************************************************************************************************
		* AID command list and mappings
		* ************************************************************************************************************************
		*/
		samsung,aid_subdivision_tx_cmds_revA = [
			29 01 00 00 00 00 03 B1 90 E2  /* 00 */
			29 01 00 00 00 00 03 B1 90 E1  /* 01 */
			29 01 00 00 00 00 03 B1 90 DF  /* 02 */
			29 01 00 00 00 00 03 B1 90 DD  /* 03 */
			29 01 00 00 00 00 03 B1 90 D3  /* 04 */
			29 01 00 00 00 00 03 B1 90 D1  /* 05 */
			29 01 00 00 00 00 03 B1 90 CF  /* 06 */
			29 01 00 00 00 00 03 B1 90 CA  /* 07 */
			29 01 00 00 00 00 03 B1 90 C3  /* 08 */
			29 01 00 00 00 00 03 B1 90 C1  /* 09 */
			29 01 00 00 00 00 03 B1 90 BF  /* 10 */
			29 01 00 00 00 00 03 B1 90 BD  /* 11 */
			29 01 00 00 00 00 03 B1 90 B3  /* 12 */
			29 01 00 00 00 00 03 B1 90 B1  /* 13 */
			29 01 00 00 00 00 03 B1 90 B0  /* 14 */
			29 01 00 00 00 00 03 B1 90 AD  /* 15 */
			29 01 00 00 00 00 03 B1 90 A3  /* 16 */
			29 01 00 00 00 00 03 B1 90 A1  /* 17 */
			29 01 00 00 00 00 03 B1 90 9F  /* 18 */
			29 01 00 00 00 00 03 B1 90 9D  /* 19 */
			29 01 00 00 00 00 03 B1 90 93  /* 20 */
			29 01 00 00 00 00 03 B1 90 92  /* 21 */
			29 01 00 00 00 00 03 B1 90 91  /* 22 */
			29 01 00 00 00 00 03 B1 90 8F  /* 23 */
			29 01 00 00 00 00 03 B1 90 8D  /* 24 */
			29 01 00 00 00 00 03 B1 90 83  /* 25 */
			29 01 00 00 00 00 03 B1 90 81  /* 26 */
			29 01 00 00 00 00 03 B1 90 7F  /* 27 */
			29 01 00 00 00 00 03 B1 90 7D  /* 28 */
			29 01 00 00 00 00 03 B1 90 73  /* 29 */
			29 01 00 00 00 00 03 B1 90 71  /* 30 */
			29 01 00 00 00 00 03 B1 90 6F  /* 31 */
			29 01 00 00 00 00 03 B1 90 6D  /* 32 */
			29 01 00 00 00 00 03 B1 90 63  /* 33 */
			29 01 00 00 00 00 03 B1 90 61  /* 34 */
			29 01 00 00 00 00 03 B1 90 57  /* 35 */
			29 01 00 00 00 00 03 B1 90 4D  /* 36 */
			29 01 00 00 00 00 03 B1 90 3F  /* 37 */
			29 01 00 00 00 00 03 B1 90 31  /* 38 */
			29 01 00 00 00 00 03 B1 90 27  /* 39 */
			29 01 00 00 00 00 03 B1 90 1D  /* 40 */
			29 01 00 00 00 00 03 B1 90 0F  /* 41 */
			29 01 00 00 00 00 03 B1 90 00  /* 42 */
			29 01 00 00 00 00 03 B1 80 F7  /* 43 */
			29 01 00 00 00 00 03 B1 80 EE  /* 44 */
			29 01 00 00 00 00 03 B1 80 E0  /* 45 */
			29 01 00 00 00 00 03 B1 80 D2  /* 46 */
			29 01 00 00 00 00 03 B1 80 C8  /* 47 */
			29 01 00 00 00 00 03 B1 80 BE  /* 48 */
			29 01 00 00 00 00 03 B1 80 B1  /* 49 */
			29 01 00 00 00 00 03 B1 80 A3  /* 50 */
			29 01 00 00 00 00 03 B1 80 99  /* 51 */
			29 01 00 00 00 00 03 B1 80 8E  /* 52 */
			29 01 00 00 00 00 03 B1 80 7F  /* 53 */
			29 01 00 00 00 00 03 B1 80 71  /* 54 */
			29 01 00 00 00 00 03 B1 80 5B  /* 55 */
			29 01 00 00 00 00 03 B1 80 45  /* 56 */
			29 01 00 00 00 00 03 B1 80 2F  /* 57 */
			29 01 00 00 00 00 03 B1 80 21  /* 58 */
			29 01 00 00 00 00 03 B1 80 13  /* 59 */
			29 01 00 00 00 00 03 B1 80 05  /* 60 */
			29 01 00 00 00 00 03 B1 70 F7  /* 61 */
			29 01 00 00 00 00 03 B1 70 DF  /* 62 */
			29 01 00 00 00 00 03 B1 70 C7  /* 63 */
			29 01 00 00 00 00 03 B1 70 BB  /* 64 */
			29 01 00 00 00 00 03 B1 70 AE  /* 65 */
			29 01 00 00 00 00 03 B1 70 96  /* 66 */
			29 01 00 00 00 00 03 B1 70 7F  /* 67 */
			29 01 00 00 00 00 03 B1 70 66  /* 68 */
			29 01 00 00 00 00 03 B1 70 4D  /* 69 */
			29 01 00 00 00 00 03 B1 70 2E  /* 70 */
			29 01 00 00 00 00 03 B1 70 13  /* 71 */
			29 01 00 00 00 00 03 B1 60 F7  /* 72 */
			29 01 00 00 00 00 03 B1 60 E3  /* 73 */
			29 01 00 00 00 00 03 B1 60 CF  /* 74 */
			29 01 00 00 00 00 03 B1 60 A9  /* 75 */
			29 01 00 00 00 00 03 B1 60 83  /* 76 */
			29 01 00 00 00 00 03 B1 60 69  /* 77 */
			29 01 00 00 00 00 03 B1 60 4F  /* 78 */
			29 01 00 00 00 00 03 B1 60 34  /* 79 */
			29 01 00 00 00 00 03 B1 60 1A  /* 80 */
			29 01 00 00 00 00 03 B1 50 F5  /* 81 */
			29 01 00 00 00 00 03 B1 50 CF  /* 82 */
			29 01 00 00 00 00 03 B1 50 A7  /* 83 */
			29 01 00 00 00 00 03 B1 50 7E  /* 84 */
			29 01 00 00 00 00 03 B1 50 57  /* 85 */
			29 01 00 00 00 00 03 B1 50 30  /* 86 */
			29 01 00 00 00 00 03 B1 50 08  /* 87 */
			29 01 00 00 00 00 03 B1 40 E1  /* 88 */
			29 01 00 00 00 00 03 B1 40 B8  /* 89 */
			29 01 00 00 00 00 03 B1 40 8E  /* 90 */
			29 01 00 00 00 00 03 B1 40 57  /* 91 */
			29 01 00 00 00 00 03 B1 40 1F  /* 92 */
			29 01 00 00 00 00 03 B1 30 E8  /* 93 */
			29 01 00 00 00 00 03 B1 30 B1  /* 94 */
			29 01 00 00 00 00 03 B1 30 D8  /* 95 */
			29 01 00 00 00 00 03 B1 30 A7  /* 96 */
			29 01 00 00 00 00 03 B1 30 D5  /* 97 */
			29 01 00 00 00 00 03 B1 30 A7  /* 98 */
			29 01 00 00 00 00 03 B1 30 DD  /* 99 */
			29 01 00 00 00 00 03 B1 30 A7  /* 100 */
			29 01 00 00 00 00 03 B1 30 D9  /* 101 */
			29 01 00 00 00 00 03 B1 30 A7  /* 102 */
			29 01 00 00 00 00 03 B1 30 D6  /* 103 */
			29 01 00 00 00 00 03 B1 30 A7  /* 104 */
			29 01 00 00 00 00 03 B1 30 DC  /* 105 */
			29 01 00 00 00 00 03 B1 30 A7  /* 106 */
			29 01 00 00 00 00 03 B1 30 D1  /* 107 */
			29 01 00 00 00 00 03 B1 30 A7  /* 108 */
			29 01 00 00 00 00 03 B1 30 DE  /* 109 */
			29 01 00 00 00 00 03 B1 30 A7  /* 110 */
			29 01 00 00 00 00 03 B1 30 D4  /* 111 */
			29 01 00 00 00 00 03 B1 30 A7  /* 112 */
			29 01 00 00 00 00 03 B1 30 DE  /* 113 */
			29 01 00 00 00 00 03 B1 30 A7  /* 114 */
			29 01 00 00 00 00 03 B1 30 D5  /* 115 */
			29 01 00 00 00 00 03 B1 30 A7  /* 116 */
			29 01 00 00 00 00 03 B1 30 D8  /* 117 */
			29 01 00 00 00 00 03 B1 30 A7  /* 118 */
			29 01 00 00 00 00 03 B1 30 DB  /* 119 */
			29 01 00 00 00 00 03 B1 30 A7  /* 120 */
			29 01 00 00 00 00 03 B1 30 D8  /* 121 */
			29 01 00 00 00 00 03 B1 30 A7  /* 122 */
			29 01 00 00 00 00 03 B1 30 DA  /* 123 */
			29 01 00 00 00 00 03 B1 30 A7  /* 124 */
			29 01 00 00 00 00 03 B1 30 D7  /* 125 */
			29 01 00 00 00 00 03 B1 30 A7  /* 126 */
			29 01 00 00 00 00 03 B1 30 D6  /* 127 */
			29 01 00 00 00 00 03 B1 30 A4  /* 128 */
			29 01 00 00 00 00 03 B1 30 91  /* 129 */
			29 01 00 00 00 00 03 B1 30 7E  /* 130 */
			29 01 00 00 00 00 03 B1 30 6B  /* 131 */
			29 01 00 00 00 00 03 B1 30 58  /* 132 */
			29 01 00 00 00 00 03 B1 30 45  /* 133 */
			29 01 00 00 00 00 03 B1 30 32  /* 134 */
			29 01 00 00 00 00 03 B1 30 1F  /* 135 */
			29 01 00 00 00 00 03 B1 30 0B  /* 136 */
			29 01 00 00 00 00 03 B1 20 F6  /* 137 */
			29 01 00 00 00 00 03 B1 20 E2  /* 138 */
			29 01 00 00 00 00 03 B1 20 CE  /* 139 */
			29 01 00 00 00 00 03 B1 20 BA  /* 140 */
			29 01 00 00 00 00 03 B1 20 A5  /* 141 */
			29 01 00 00 00 00 03 B1 20 91  /* 142 */
			29 01 00 00 00 00 03 B1 20 7C  /* 143 */
			29 01 00 00 00 00 03 B1 20 68  /* 144 */
			29 01 00 00 00 00 03 B1 20 53  /* 145 */
			29 01 00 00 00 00 03 B1 20 3E  /* 146 */
			29 01 00 00 00 00 03 B1 20 29  /* 147 */
			29 01 00 00 00 00 03 B1 20 15  /* 148 */
			29 01 00 00 00 00 03 B1 20 00  /* 149 */
			29 01 00 00 00 00 03 B1 10 EA  /* 150 */
			29 01 00 00 00 00 03 B1 10 D4  /* 151 */
			29 01 00 00 00 00 03 B1 10 BE  /* 152 */
			29 01 00 00 00 00 03 B1 10 A8  /* 153 */
			29 01 00 00 00 00 03 B1 10 92  /* 154 */
			29 01 00 00 00 00 03 B1 10 7C  /* 155 */
			29 01 00 00 00 00 03 B1 10 66  /* 156 */
			29 01 00 00 00 00 03 B1 10 50  /* 157 */
			29 01 00 00 00 00 03 B1 10 7E  /* 158 */
			29 01 00 00 00 00 03 B1 10 6C  /* 159 */
			29 01 00 00 00 00 03 B1 10 5B  /* 160 */
			29 01 00 00 00 00 03 B1 10 49  /* 161 */
			29 01 00 00 00 00 03 B1 10 38  /* 162 */
			29 01 00 00 00 00 03 B1 10 26  /* 163 */
			29 01 00 00 00 00 03 B1 10 15  /* 164 */
			29 01 00 00 00 00 03 B1 10 03  /* 165 */
			29 01 00 00 00 00 03 B1 10 80  /* 166 */
			29 01 00 00 00 00 03 B1 10 70  /* 167 */
			29 01 00 00 00 00 03 B1 10 61  /* 168 */
			29 01 00 00 00 00 03 B1 10 51  /* 169 */
			29 01 00 00 00 00 03 B1 10 41  /* 170 */
			29 01 00 00 00 00 03 B1 10 32  /* 171 */
			29 01 00 00 00 00 03 B1 10 22  /* 172 */
			29 01 00 00 00 00 03 B1 10 13  /* 173 */
			29 01 00 00 00 00 03 B1 10 03  /* 174 */
			29 01 00 00 00 00 03 B1 10 80  /* 175 */
			29 01 00 00 00 00 03 B1 10 70  /* 176 */
			29 01 00 00 00 00 03 B1 10 60  /* 177 */
			29 01 00 00 00 00 03 B1 10 51  /* 178 */
			29 01 00 00 00 00 03 B1 10 41  /* 179 */
			29 01 00 00 00 00 03 B1 10 32  /* 180 */
			29 01 00 00 00 00 03 B1 10 22  /* 181 */
			29 01 00 00 00 00 03 B1 10 13  /* 182 */
			29 01 00 00 00 00 03 B1 10 03  /* 183 */
			29 01 00 00 00 00 03 B1 10 81  /* 184 */
			29 01 00 00 00 00 03 B1 10 73  /* 185 */
			29 01 00 00 00 00 03 B1 10 65  /* 186 */
			29 01 00 00 00 00 03 B1 10 57  /* 187 */
			29 01 00 00 00 00 03 B1 10 49  /* 188 */
			29 01 00 00 00 00 03 B1 10 3B  /* 189 */
			29 01 00 00 00 00 03 B1 10 2D  /* 190 */
			29 01 00 00 00 00 03 B1 10 1F  /* 191 */
			29 01 00 00 00 00 03 B1 10 11  /* 192 */
			29 01 00 00 00 00 03 B1 10 03  /* 193 */
			29 01 00 00 00 00 03 B1 10 6A  /* 194 */
			29 01 00 00 00 00 03 B1 10 5B  /* 195 */
			29 01 00 00 00 00 03 B1 10 4D  /* 196 */
			29 01 00 00 00 00 03 B1 10 3E  /* 197 */
			29 01 00 00 00 00 03 B1 10 2F  /* 198 */
			29 01 00 00 00 00 03 B1 10 20  /* 199 */
			29 01 00 00 00 00 03 B1 10 12  /* 200 */
			29 01 00 00 00 00 03 B1 10 03  /* 201 */
			29 01 00 00 00 00 03 B1 10 6D  /* 202 */
			29 01 00 00 00 00 03 B1 10 5F  /* 203 */
			29 01 00 00 00 00 03 B1 10 52  /* 204 */
			29 01 00 00 00 00 03 B1 10 45  /* 205 */
			29 01 00 00 00 00 03 B1 10 38  /* 206 */
			29 01 00 00 00 00 03 B1 10 2B  /* 207 */
			29 01 00 00 00 00 03 B1 10 1D  /* 208 */
			29 01 00 00 00 00 03 B1 10 10  /* 209 */
			29 01 00 00 00 00 03 B1 10 03  /* 210 */
			29 01 00 00 00 00 03 B1 10 67  /* 211 */
			29 01 00 00 00 00 03 B1 10 5B  /* 212 */
			29 01 00 00 00 00 03 B1 10 4E  /* 213 */
			29 01 00 00 00 00 03 B1 10 42  /* 214 */
			29 01 00 00 00 00 03 B1 10 35  /* 215 */
			29 01 00 00 00 00 03 B1 10 29  /* 216 */
			29 01 00 00 00 00 03 B1 10 1C  /* 217 */
			29 01 00 00 00 00 03 B1 10 10  /* 218 */
			29 01 00 00 00 00 03 B1 10 03  /* 219 */
			29 01 00 00 00 00 03 B1 10 25  /* 220 */
			29 01 00 00 00 00 03 B1 10 1A  /* 221 */
			29 01 00 00 00 00 03 B1 10 0E  /* 222 */
			29 01 00 00 00 00 03 B1 10 03  /* 223 */
			29 01 00 00 00 00 03 B1 10 29  /* 224 */
			29 01 00 00 00 00 03 B1 10 1C  /* 225 */
			29 01 00 00 00 00 03 B1 10 10  /* 226 */
			29 01 00 00 00 00 03 B1 10 03  /* 227 */
			29 01 00 00 00 00 03 B1 00 EE  /* 228 */
			29 01 00 00 00 00 03 B1 00 D8  /* 229 */
			29 01 00 00 00 00 03 B1 00 C3  /* 230 */
			29 01 00 00 00 00 03 B1 00 B5  /* 231 */
			29 01 00 00 00 00 03 B1 00 A6  /* 232 */
			29 01 00 00 00 00 03 B1 00 98  /* 233 */
			29 01 00 00 00 00 03 B1 00 8A  /* 234 */
			29 01 00 00 00 00 03 B1 00 7D  /* 235 */
			29 01 00 00 00 00 03 B1 00 70  /* 236 */
			29 01 00 00 00 00 03 B1 00 64  /* 237 */
			29 01 00 00 00 00 03 B1 00 57  /* 238 */
			29 01 00 00 00 00 03 B1 00 45  /* 239 */
			29 01 00 00 00 00 03 B1 00 33  /* 240 */
			29 01 00 00 00 00 03 B1 00 22  /* 241 */
			29 01 00 00 00 00 03 B1 00 10  /* 242 */
			29 01 00 00 00 00 03 B1 00 32  /* 243 */
			29 01 00 00 00 00 03 B1 00 26  /* 244 */
			29 01 00 00 00 00 03 B1 00 19  /* 245 */
			29 01 00 00 00 00 03 B1 00 0C  /* 246 */
			29 01 00 00 00 00 03 B1 00 36  /* 247 */
			29 01 00 00 00 00 03 B1 00 28  /* 248 */
			29 01 00 00 00 00 03 B1 00 1A  /* 249 */
			29 01 00 00 00 00 03 B1 00 0C  /* 250 */
			29 01 00 00 00 00 03 B1 00 31  /* 251 */
			29 01 00 00 00 00 03 B1 00 24  /* 252 */
			29 01 00 00 00 00 03 B1 00 18  /* 253 */
			29 01 00 00 00 00 03 B1 00 0C  /* 254 */
			29 01 00 00 00 00 03 B1 00 0C  /* 255 */
		];
		samsung,panel_multires_fhd_to_wqhd_revA = [
			29 00 00 00 05 00 03 F0 5A 5A		/* TEST KEY1 Enable */

			29 00 00 00 00 00 05 2A 00 00 05 9F	/* CASET PASET */
			29 00 00 00 00 00 05 2B 00 00 09 FF

			29 00 00 00 00 00 02 B0 08
			29 00 00 00 00 00 03 F2 04 B0		/* CASET/PASET 2Ch latch X, PPS 2Ch latch O, Scaler on/off 2Ch latch O, Black frame insertion X*/

			0A 01 00 00 0A 00 58				/* PPS setting wqhd */
				11 00 00 89 30 80 0A
				00 05 A0 00 20 02 D0
				02 D0 02 00 02 68 00
				20 03 87 00 0A 00 0C
				03 19 02 63 18 00 10
				F0 03 0C 20 00 06 0B
				0B 33 0E 1C 2A 38 46
				54 62 69 70 77 79 7B
				7D 7E 01 02 01 00 09
				40 09 BE 19 FC 19 FA
				19 F8 1A 38 1A 78 1A
				B6 2A F6 2B 34 2B 74
				3B 74 6B F4

			29 00 00 00 00 00 02 BA 03			/* scaler setup */

			29 01 00 00 00 00 03 F0 A5 A5		/* TEST KEY Disable */
		];

		samsung,panel_multires_hd_to_wqhd_revA = [
			29 00 00 00 05 00 03 F0 5A 5A		/* TEST KEY1 Enable */

			29 00 00 00 00 00 05 2A 00 00 05 9F	/* CASET PASET */
			29 00 00 00 00 00 05 2B 00 00 09 FF

			29 00 00 00 00 00 02 B0 08
			29 00 00 00 00 00 03 F2 04 B0		/* CASET/PASET 2Ch latch X, PPS 2Ch latch O, Scaler on/off 2Ch latch O, Black frame insertion X*/

			0A 01 00 00 0A 00 58				/* PPS setting wqhd */
				11 00 00 89 30 80 0A
				00 05 A0 00 20 02 D0
				02 D0 02 00 02 68 00
				20 03 87 00 0A 00 0C
				03 19 02 63 18 00 10
				F0 03 0C 20 00 06 0B
				0B 33 0E 1C 2A 38 46
				54 62 69 70 77 79 7B
				7D 7E 01 02 01 00 09
				40 09 BE 19 FC 19 FA
				19 F8 1A 38 1A 78 1A
				B6 2A F6 2B 34 2B 74
				3B 74 6B F4

			29 00 00 00 00 00 02 BA 01			/* scaler setup */

			29 01 00 00 00 00 03 F0 A5 A5		/* TEST KEY Disable */
		];

		samsung,panel_multires_fhd_revA = [
			29 00 00 00 05 00 03 F0 5A 5A		/* TEST KEY1 Enable */

			29 00 00 00 00 00 05 2A 00 00 04 37	/* CASET PASET */
			29 00 00 00 00 00 05 2B 00 00 07 7F

			29 00 00 00 00 00 02 B0 08
			29 00 00 00 00 00 03 F2 04 B0		/* CASET/PASET 2Ch latch X, PPS 2Ch latch O, Scaler on/off 2Ch latch O, Black frame insertion X*/

			0A 01 00 00 0A 00 58				/* PPS setting fhd */
				11 00 00 89 30 80 07
				80 04 38 00 20 02 1C
				02 1C 02 00 02 0E 00
				20 03 15 00 07 00 0C
				03 19 03 2E 18 00 10
				F0 03 0C 20 00 06 0B
				0B 33 0E 1C 2A 38 46
				54 62 69 70 77 79 7B
				7D 7E 01 02 01 00 09
				40 09 BE 19 FC 19 FA
				19 F8 1A 38 1A 78 1A
				B6 2A F6 2B 34 2B 74
				3B 74 6B F4

			29 00 00 00 00 00 02 BA 02			/* scaler setup */

			29 01 00 00 00 00 03 F0 A5 A5	/* TEST KEY Disable */
		];

		samsung,panel_multires_hd_revA = [
			29 00 00 00 05 00 03 F0 5A 5A		/* TEST KEY1 Enable */

			29 00 00 00 00 00 05 2A 00 00 02 CF	/* CASET PASET */
			29 00 00 00 00 00 05 2B 00 00 04 FF

			29 00 00 00 00 00 02 B0 08
			29 00 00 00 00 00 03 F2 04 B0		/* CASET/PASET 2Ch latch X, PPS 2Ch latch O, Scaler on/off 2Ch latch O, Black frame insertion X*/

			0A 01 00 00 0A 00 58				/* PPS setting hd */
				11 00 00 89 30 80 05
				00 02 D0 00 40 01 68
				01 68 02 00 01 B4 00
				20 04 F2 00 05 00 0C
				01 87 02 63 18 00 10
				F0 03 0C 20 00 06 0B
				0B 33 0E 1C 2A 38 46
				54 62 69 70 77 79 7B
				7D 7E 01 02 01 00 09
				40 09 BE 19 FC 19 FA
				19 F8 1A 38 1A 78 1A
				B6 2A F6 2B 34 2B 74
				3B 74 6B F4

			29 00 00 00 00 00 02 BA 00			/* scaler setup */

			29 01 00 00 00 00 03 F0 A5 A5		/* TEST KEY Disable */
		];
		/*
		* ************************************************************************************************************************
		* ACL command list and mappings
		* ************************************************************************************************************************
		*/
		samsung,acl_on_tx_cmds_revA = [
			29 01 00 00 00 00 08 B4 00 55 7F 00 00 27 12  /* 2nd : 0x55 32frame avg, 3rd : 0x7F start point 50%, 7th: 0x12 ACL 15% */
			29 01 00 00 00 00 02 55 02	/* ACL ON */
		]; /* ACL on */

		samsung,acl_percent_tx_cmds_revA = [
			29 01 00 00 00 00 08 B4 00 55 7F 00 00 27 0A  /* 2nd : 0x55 32frame avg, 3rd : 0x7F start point 50%, 7th: 0xA ACL  8% */
			29 01 00 00 00 00 08 B4 00 55 7F 00 00 27 12  /* 2nd : 0x55 32frame avg, 3rd : 0x7F start point 50%, 7th: 0x12 ACL 15% */
		];

		samsung,acl_off_tx_cmds_revA = [
			29 01 00 00 00 00 08 B4 00 44 7F 00 00 27 00  /* 2nd : 0x44 16frame avg, 3rd : 0x7F start point 50%, 7th: 0x00 ACL Off */
			29 01 00 00 00 00 02 55 00	 /* ACL OFF */
		];

		samsung,gradual_acl_tx_cmds_revA = [
			29 01 00 00 00 00 08 B4 00 55 7F 00 00 27 00  /* 2nd : 0x55 32frame avg, 3rd : 0x7F start point 50%, 7th: 0xA ACL  8% */
		];

		/* bl_level , Index in acl command list */
		samsung,acl_map_table_revA =  <
			2	1		3	1		4	1		5	1		6	1
			7	1		8	1		9	1		10	1		11	1
			12	1		13	1		14	1		15	1		16	1
			17	1		19	1		20	1		21	1		22	1
			24	1		25	1		27	1		29	1		30	1
			32	1		34	1		37	1		39	1		41	1
			44	1		47	1		50	1		53	1		56	1
			60	1		64	1		68	1		72	1		77	1
			82	1		87	1		93	1		98	1		105	1
			111	1		119	1		126	1		134	1		143	1
			152	1		162	1		172	1		183	1		195	1
			207	1		220	1		234	1		249	1		265	1
			282	1		300	1		316	1		333	1		350	1
			357	1		365	1		372	1		380	1		387	1
			395	1		403	1		412	1		420	1
		>;

		/*
		* ************************************************************************************************************************
		* ELVSS command list and mappings
		* ************************************************************************************************************************
		*/

		samsung,elvss_rx_cmds_revA = [ 06 01 00 00 00 00 01 B5 02 17];	/* read B5 24,25th , 23=0x17*/

		samsung,elvss_lowtemp_tx_cmds_revA = [
			29 01 00 00 00 00 02 B5 00 /* TSET */
			29 01 00 00 00 00 02 B0 17
			29 01 00 00 00 00 02 B5 00 /* elvss offset */
		];

		samsung,elvss_tx_cmds_revA = [
			29 01 00 00 00 00 04 B5 19 BC 0A /* 420CD 0 */
			29 01 00 00 00 00 04 B5 19 BC 0A /* 412CD 1 */
			29 01 00 00 00 00 04 B5 19 BC 0B /* 403CD 2 */
			29 01 00 00 00 00 04 B5 19 BC 0B /* 395CD 3 */
			29 01 00 00 00 00 04 B5 19 BC 0B /* 387CD 4 */
			29 01 00 00 00 00 04 B5 19 BC 0C /* 380CD 5 */
			29 01 00 00 00 00 04 B5 19 BC 0C /* 372CD 6 */
			29 01 00 00 00 00 04 B5 19 BC 0C /* 365CD 7 */
			29 01 00 00 00 00 04 B5 19 BC 0C /* 357CD 8 */
			29 01 00 00 00 00 04 B5 19 BC 0D /* 350CD 9 */
			29 01 00 00 00 00 04 B5 19 BC 0D /* 333CD 10 */
			29 01 00 00 00 00 04 B5 19 BC 0E /* 316CD 11 */
			29 01 00 00 00 00 04 B5 19 BC 0F /* 300CD 12 */
			29 01 00 00 00 00 04 B5 19 BC 10 /* 282CD 13 */
			29 01 00 00 00 00 04 B5 19 BC 11 /* 265CD 14 */
			29 01 00 00 00 00 04 B5 19 BC 12 /* 249CD 15 */
			29 01 00 00 00 00 04 B5 19 BC 12 /* 234CD 16 */
			29 01 00 00 00 00 04 B5 19 BC 12 /* 220CD 17 */
			29 01 00 00 00 00 04 B5 19 BC 12 /* 207CD 18 */
			29 01 00 00 00 00 04 B5 19 BC 12 /* 195CD 19 */
			29 01 00 00 00 00 04 B5 19 BC 12 /* 183CD 20 */
			29 01 00 00 00 00 04 B5 19 BC 13 /* 172CD 21 */
			29 01 00 00 00 00 04 B5 19 BC 13 /* 162CD 22 */
			29 01 00 00 00 00 04 B5 19 BC 13 /* 152CD 23 */
			29 01 00 00 00 00 04 B5 19 BC 14 /* 143CD 24 */
			29 01 00 00 00 00 04 B5 19 BC 15 /* 134CD 25 */
			29 01 00 00 00 00 04 B5 19 BC 15 /* 126CD 26*/
			29 01 00 00 00 00 04 B5 19 BC 16 /* 119CD 27*/
			29 01 00 00 00 00 04 B5 19 BC 16 /* 111CD 28*/
			29 01 00 00 00 00 04 B5 19 BC 17 /* 105CD 29*/
			29 01 00 00 00 00 04 B5 19 BC 17 /* 98CD  30*/
			29 01 00 00 00 00 04 B5 19 BC 17 /* 93CD  31*/
			29 01 00 00 00 00 04 B5 19 BC 18 /* 87CD  32*/
			29 01 00 00 00 00 04 B5 19 BC 18 /* 82CD  33*/
			29 01 00 00 00 00 04 B5 19 BC 19 /* 77 ~ 41CD 34*/
			29 01 00 00 00 00 04 B5 19 AC 19 /* 39 ~ 6CD 35 */
			29 01 00 00 00 00 04 B5 19 AC 18 /*  5CD 36 */
			29 01 00 00 00 00 04 B5 19 AC 17 /*  4CD 37 */
			29 01 00 00 00 00 04 B5 19 AC 16 /*  3CD 38 */
			29 01 00 00 00 00 04 B5 19 AC 15 /*  2CD 39 */
		];

		/* bl_level, Index in elvss command list */
		samsung,smart_acl_elvss_map_table_revA = <
			2	39		3	38		4	37		5	36		6	35
			7	35		8	35		9	35		10	35		11	35
			12	35		13	35		14	35		15	35		16	35
			17	35		19	35		20	35		21	35		22	35
			24	35		25	35		27	35		29	35		30	35
			32	35		34	35		37	35		39	35		41	34
			44	34		47	34		50	34		53	34		56	34
			60	34		64	34		68	34		72	34		77	34
			82	33		87	32		93	31		98	30		105	29
			111	28		119	27		126	26		134	25		143	24
			152	23		162	22		172	21		183	20		195	19
			207	18		220	17		234	16		249	15		265	14
			282	13		300	12		316	11		333	10		350	9
			357	8		365	7		372	6		380	5		387	4
			395	3		403	2		412	1		420	0
		>;

		/*
		* ************************************************************************************************************************
		* candela to index mappings
		* ************************************************************************************************************************
		*/
		samsung,candela_map_table_revA = <
			/*<idx>   <from>  <till> <candella> */
			0	0	0	2
			1	1	7	3
			2	8	14	4
			3	15	21	5
			4	22	28	6
			5	29	34	7
			6	35	36	8
			7	37	38	9
			8	39	40	10
			9	41	42	11
			10	43	44	12
			11	45	46	13
			12	47	48	14
			13	49	50	15
			14	51	52	16
			15	53	54	17
			16	55	56	19
			17	57	57	20
			18	58	59	21
			19	60	61	22
			20	62	63	24
			21	64	65	25
			22	66	67	27
			23	68	69	29
			24	70	70	30
			25	71	72	32
			26	73	74	34
			27	75	76	37
			28	77	78	39
			29	79	80	41
			30	81	82	44
			31	83	84	47
			32	85	86	50
			33	87	88	53
			34	89	90	56
			35	91	92	60
			36	93	94	64
			37	95	96	68
			38	97	98	72
			39	99	100	77
			40	101	102	82
			41	103	104	87
			42	105	106	93
			43	107	108	98
			44	109	110	105
			45	111	112	111
			46	113	114	119
			47	115	116	126
			48	117	118	134
			49	119	120	143
			50	121	122	152
			51	123	124	162
			52	125	126	172
			53	127	128	183
			54	129	135	195
			55	136	142	207
			56	143	149	220
			57	150	157	234
			58	158	165	249
			59	166	174	265
			60	175	183	282
			61	184	193	300
			62	194	201	316
			63	202	210	333
			64	211	219	350
			65	220	223	357
			66	224	227	365
			67	228	230	372
			68	231	234	380
			69	235	238	387
			70	239	242	395
			71	243	246	403
			72	247	250	412
			73	251	255	420
		>;

		samsung,hbm_candela_map_table_revA = <
			0	282	295	465	6
			1	296	309	488	7
			2	310	323	510	8
			3	324	336	533	9
			4	337	350	555	10
			5	351	364	578	11
			6	365	365	600	12
		>;
		/*
		* ************************************************************************************************************************
		*  HMT
		* ************************************************************************************************************************
		*/

		samsung,hmt_enabled;

		samsung,hmt_aid_tx_cmds_revA = [
			29 01 00 00 00 00 05 B1 20 05 0C 00   /*10cd */
			29 01 00 00 00 00 05 B1 20 05 0C 00   /*11cd */
			29 01 00 00 00 00 05 B1 20 05 0C 00   /*12cd */
			29 01 00 00 00 00 05 B1 20 05 0C 00   /*13cd */
			29 01 00 00 00 00 05 B1 20 05 0C 00   /*14cd */
			29 01 00 00 00 00 05 B1 20 05 0C 00   /*15cd */
			29 01 00 00 00 00 05 B1 20 05 0C 00   /*16cd */
			29 01 00 00 00 00 05 B1 20 05 0C 00   /*17cd */
			29 01 00 00 00 00 05 B1 20 05 0C 00   /*19cd */
			29 01 00 00 00 00 05 B1 20 05 0C 00   /*20cd */
			29 01 00 00 00 00 05 B1 20 05 0C 00   /*21cd */
			29 01 00 00 00 00 05 B1 20 05 0C 00   /*22cd */
			29 01 00 00 00 00 05 B1 20 05 0C 00   /*23cd */
			29 01 00 00 00 00 05 B1 20 05 0C 00   /*25cd */
			29 01 00 00 00 00 05 B1 20 05 0C 00   /*27cd */
			29 01 00 00 00 00 05 B1 20 05 0C 00   /*29cd */
			29 01 00 00 00 00 05 B1 20 05 0C 00   /*31cd */
			29 01 00 00 00 00 05 B1 20 05 0C 00   /*33cd */
			29 01 00 00 00 00 05 B1 20 05 0C 00   /*35cd */
			29 01 00 00 00 00 05 B1 20 05 0C 00   /*37cd */
			29 01 00 00 00 00 05 B1 20 05 0C 00   /*39cd */
			29 01 00 00 00 00 05 B1 20 05 0C 00   /*41cd */
			29 01 00 00 00 00 05 B1 20 05 0C 00   /*44cd */
			29 01 00 00 00 00 05 B1 20 05 0C 00   /*47cd */
			29 01 00 00 00 00 05 B1 20 05 0C 00   /*50cd */
			29 01 00 00 00 00 05 B1 20 05 0C 00   /*53cd */
			29 01 00 00 00 00 05 B1 20 05 0C 00   /*56cd */
			29 01 00 00 00 00 05 B1 20 05 0C 00   /*60cd */
			29 01 00 00 00 00 05 B1 20 05 0C 00   /*64cd */
			29 01 00 00 00 00 05 B1 20 05 0C 00   /*68cd */
			29 01 00 00 00 00 05 B1 20 05 0C 00   /*72cd */
			29 01 00 00 00 00 05 B1 30 07 0C 00   /*77cd */
			29 01 00 00 00 00 05 B1 30 07 0C 00   /*82cd */
			29 01 00 00 00 00 05 B1 30 07 0C 00   /*87cd */
			29 01 00 00 00 00 05 B1 30 07 0C 00   /*93cd */
			29 01 00 00 00 00 05 B1 30 07 0C 00   /*99cd */
			29 01 00 00 00 00 05 B1 30 07 0C 00   /*105cd */
		];

		/* bl_level, Index in acl command list */
		samsung,hmt_reverse_aid_map_table_revA = <
			10	0
			11	1
			12	2
			13	3
			14	4
			15	5
			16	6
			17	7
			19	8
			20	9
			21	10
			22	11
			23	12
			25	13
			27	14
			29	15
			31	16
			33	17
			35	18
			37	19
			39	20
			41	21
			44	22
			47	23
			50	24
			53	25
			56	26
			60	27
			64	28
			68	29
			72	30
			77	31
			82	32
			87	33
			93	34
			99	35
			105	36
		>;

		samsung,hmt_candela_map_table_revA = <
		/*<idx>	  <from>  <till> <candella> */
			0	0	26	10
			1	27	29	11
			2	30	31	12
			3	32	33	13
			4	34	36	14
			5	37	38	15
			6	39	41	16
			7	42	46	17
			8	47	48	19
			9	49	50	20
			10	51	53	21
			11	54	55	22
			12	56	60	23
			13	61	65	25
			14	66	70	27
			15	71	75	29
			16	76	80	31
			17	81	84	33
			18	85	89	35
			19	90	94	37
			20	95	99	39
			21	100	106	41
			22	107	114	44
			23	115	121	47
			24	122	128	50
			25	129	135	53
			26	136	145	56
			27	146	155	60
			28	156	165	64
			29	166	174	68
			30	175	186	72
			31	187	199	77
			32	200	211	82
			33	212	225	87
			34	226	240	93
			35	241	254	99
			36	255	255	105
		>;

		samsung,hmt_gamma_tx_cmds_revA = [
			29 01 00 00 00 00 24
				CA 01 00 01 00 01 00 80
				80 80 80 80 80 80 80 80
				80 80 80 80 80 80 80 80
				80 80 80 80 80 80 80 00
				00 00 00 00

			29 01 00 00 00 00 05 B4 40 7F 27 12  /* 1th : 0x50 32frame avg, 2th : 0x7F start point 50%, 4th: don't care*/
			29 01 00 00 00 00 02 55 00	 /* ACL OFF */

			29 01 00 00 01 00 02 F7 03		/* Gamma, LTPS(AID) update */
			29 01 00 00 00 00 02 F7 00
		];

		samsung,hmt_elvss_tx_cmds_revA = [
				29 01 00 00 00 00 02 B0 01
				29 01 00 00 00 00 03 B5 00 0A
		];

		samsung,hmt_vint_tx_cmds_revA = [
				29 01 00 00 00 00 03 F4 BB 1E
		];

		samsung,hmt_enable_tx_cmds_revA = [
				29 01 00 00 00 00 03 F0 5A 5A
				29 01 00 00 00 00 05 B1 30 07 0C 80 	/* AID 1-Cycle */
				29 01 00 00 00 00 03 F0 A5 A5
			];

		samsung,hmt_disable_tx_cmds_revA = [
				29 01 00 00 00 00 03 F0 5A 5A
				29 01 00 00 00 00 05 B1 30 07 0C 80 	/* AID 1-Cycle */
				29 01 00 00 01 00 02 F7 03				/* Gamma, LTPS(AID) update */
				29 01 00 00 00 00 02 F7 00
				29 01 00 00 00 00 03 F0 A5 A5
			];

		samsung,hmt_reverse_tx_cmds_revA = [
				29 01 00 00 00 00 03 F0 5A 5A
				29 01 00 00 00 00 34 CB					/* LTPS setting */
					12 01 81 01 90 61 81 00
					00 00 00 00 22 80 89 00
					00 03 0D 00 12 9B 00 00
					00 00 15 00 00 00 00 00
					00 B0 00 00 C0 11 13 05
					4E 46 C3 00 00 C0 C0 C0
					C0 D1 93
				29 01 00 00 01 00 02 F7 03				/* Gamma, LTPS(AID) update */
				29 01 00 00 00 00 02 F7 00
				29 01 00 00 00 00 03 F0 A5 A5
			];

		samsung,hmt_forward_tx_cmds_revA = [
				29 01 00 00 00 00 03 F0 5A 5A
				29 01 00 00 00 00 34 CB					/* LTPS setting */
					12 01 81 01 90 61 81 00
					00 00 00 00 22 80 89 00
					00 0B 05 00 12 9B 00 00
					00 00 09 00 00 00 00 00
					00 B0 00 00 C0 11 13 05
					4E 46 C3 00 00 C0 C0 C0
					C0 D1 13
				29 01 00 00 01 00 02 F7 03				/* Gamma, LTPS(AID) update */
				29 01 00 00 00 00 02 F7 00
				29 01 00 00 00 00 03 F0 A5 A5
			];

		/*
		* ************************************************************************************************************************
		*  MULTI_RESOLUTION (DSC configs were moved all to below timing set)
		* ************************************************************************************************************************
		*/

		qcom,mdss-dsi-display-timings {
			wqhd {
				qcom,mdss-dsi-timing-default;
				qcom,mdss-dsi-panel-width = <1440>;
				qcom,mdss-dsi-panel-height = <2560>;
				qcom,mdss-dsi-h-pulse-width = <52>;
				qcom,mdss-dsi-h-back-porch = <156>;
				qcom,mdss-dsi-h-front-porch = <152>;
				qcom,mdss-dsi-h-sync-skew = <0>;
				qcom,mdss-dsi-v-pulse-width = <100>;
				qcom,mdss-dsi-v-back-porch = <160>;
				qcom,mdss-dsi-v-front-porch = <150>;
				qcom,mdss-dsi-panel-framerate = <60>;
				qcom,mdss-dsi-panel-timings = [FE 56 3C 00 74 88 3C 56 4A 03 04 A0];
				/*qcom,mdss-dsi-timing-switch-command; use samsung,panel_multires_XXX instead*/
				/*qcom,mdss-dsi-timing-switch-command-state;*/
				qcom,mdss-dsi-t-clk-pre = <0x30>;
				qcom,mdss-dsi-t-clk-post = <0x0D>;

				qcom,mdss-dsi-panel-timings-phy-v2 = [
					24 1F 08 09 05 03 04 a0
					24 1F 08 09 05 03 04 a0
					24 1F 08 09 05 03 04 a0
					24 1F 08 09 05 03 04 a0
					24 1B 08 09 05 03 04 a0
				];
				qcom,mdss-dsi-on-command = [
					29 00 00 00 05 00 03 F0 5A 5A		/* TEST KEY1 Enable - 5ms */

					/* DSC setting */
					07 01 00 00 00 00 01 01				/* DSC enable */

					05 01 00 00 78 00 01 11				/* Sleep out (Wait 120ms) */

					/* Sleep out, wait 120 ms */

					29 00 00 00 00 00 02 B0 02
					29 00 00 00 00 00 02 F6 97			/* Source status refresh */

					29 01 00 00 00 00 03 9F A5 A5		/* LV1 (9F) unlock */
					29 00 00 00 00 00 02 35 00			/* TE Vsync ON */
					29 01 00 00 00 00 03 9F 5A 5A		/* LV1 (9F) lock */

					29 00 00 00 00 00 02 B0 05			/* Touch Vsync&Hsync Enable */
					29 00 00 00 00 00 07 B9 11 03 02 40 02 40

					29 00 00 00 00 00 02 ED 44			/* ERR_FG */

					/* TE Start Timing */
					29 00 00 00 00 00 06 B9 01 0A 0E 0A 17

					/* FFC Setting (898Mbps) */
					29 00 00 00 00 00 03 FC 5A 5A		/* TEST KEY2 Enable */
					29 00 00 00 00 00 0E CE 0D 58 1B 43 0A 1C 60 73 00 FF 02 11 0B
					29 00 00 00 00 00 03 FC A5 A5		/* TEST KEY2 Disable */

					29 00 00 00 00 00 05 2A 00 00 05 9F	/* CASET PASET */
					29 00 00 00 00 00 05 2B 00 00 09 FF

					0A 01 00 00 0A 00 58				/* PPS setting wqhd */
						11 00 00 89 30 80 0A
						00 05 A0 00 20 02 D0
						02 D0 02 00 02 68 00
						20 03 87 00 0A 00 0C
						03 19 02 63 18 00 10
						F0 03 0C 20 00 06 0B
						0B 33 0E 1C 2A 38 46
						54 62 69 70 77 79 7B
						7D 7E 01 02 01 00 09
						40 09 BE 19 FC 19 FA
						19 F8 1A 38 1A 78 1A
						B6 2A F6 2B 34 2B 74
						3B 74 6B F4

					29 00 00 00 00 00 02 BA 01			/* scaler setup */

					29 00 00 00 00 00 24				/* Brightness condition set */
						CA
						01 00 01 00 01 00
						80 80 80
						80 80 80
						80 80 80
						80 80 80
						80 80 80
						80 80 80
						80 80 80
						80 80 80
						00 00 00
						00 00
					29 00 00 00 00 00 03 B1 00 0C		/* AID 0% */
					29 00 00 00 00 00 02 B0 01
					29 00 00 00 00 00 03 B5 BC 0A		/* ELVSS Setting:CAPS ON : acl off */
					29 00 00 00 00 00 03 F4 BB 1E		/* VINT set */

					29 01 00 00 01 00 02 F7 03			/* Gamma, LTPS(AID) update wait more 100ns */
					29 00 00 00 00 00 02 F7 00

					29 01 00 00 00 00 02 B0 04
					29 01 00 00 00 00 03 F2 1C 70		/* LDI FPS Recovery(59.835hz) */

					29 01 00 00 00 00 03 F0 A5 A5		/* TEST KEY key Disable  */
				];
				qcom,mdss-dsi-on-command-state = "dsi_lp_mode";
				qcom,panel-roi-alignment=<720 32 720 32 720 32>;
				qcom,compression-mode = "dsc";
				qcom,config-select = <&dsc_wqhd>;
				dsc_wqhd: config_wqhd {
					qcom,lm-split = <720 720>;
					qcom,mdss-dsc-encoders = <2>;
					qcom,mdss-dsc-slice-height = <32>;
					qcom,mdss-dsc-slice-width = <720>;
					qcom,mdss-dsc-slice-per-pkt = <1>;

					qcom,mdss-dsc-bit-per-component = <8>;
					qcom,mdss-dsc-bit-per-pixel = <8>;
					qcom,mdss-dsc-block-prediction-enable;
				};
			};
			fhd {
				qcom,mdss-dsi-panel-width = <1080>;
				qcom,mdss-dsi-panel-height = <1920>;
				qcom,mdss-dsi-h-pulse-width = <52>;
				qcom,mdss-dsi-h-back-porch = <276>;
				qcom,mdss-dsi-h-front-porch = <152>;
				qcom,mdss-dsi-h-sync-skew = <0>;
				qcom,mdss-dsi-v-pulse-width = <100>;
				qcom,mdss-dsi-v-back-porch = <160>;
				qcom,mdss-dsi-v-front-porch = <790>;
				qcom,mdss-dsi-panel-framerate = <60>;
				qcom,mdss-dsi-panel-timings = [FE 56 3C 00 74 88 3C 56 4A 03 04 A0];
				/*qcom,mdss-dsi-timing-switch-command; use samsung,panel_multires_XXX instead*/
				/*qcom,mdss-dsi-timing-switch-command-state;*/
				qcom,mdss-dsi-t-clk-pre = <0x30>;
				qcom,mdss-dsi-t-clk-post = <0x0D>;

				qcom,mdss-dsi-panel-timings-phy-v2 = [
					24 1F 08 09 05 03 04 a0
					24 1F 08 09 05 03 04 a0
					24 1F 08 09 05 03 04 a0
					24 1F 08 09 05 03 04 a0
					24 1B 08 09 05 03 04 a0
				];
				qcom,mdss-dsi-on-command = [
					29 00 00 00 05 00 03 F0 5A 5A		/* TEST KEY1 Enable - 5ms */

					/* DSC setting */
					07 01 00 00 00 00 01 01				/* DSC enable */

					05 01 00 00 78 00 01 11				/* Sleep out (Wait 120ms) */

					/* Sleep out, wait 120 ms */

					29 00 00 00 00 00 02 B0 02
					29 00 00 00 00 00 02 F6 97			/* Source status refresh */

					29 01 00 00 00 00 03 9F A5 A5		/* LV1 (9F) unlock */
					29 00 00 00 00 00 02 35 00			/* TE Vsync ON */
					29 01 00 00 00 00 03 9F 5A 5A		/* LV1 (9F) lock */

					29 00 00 00 00 00 02 B0 05			/* Touch Vsync&Hsync Enable */
					29 00 00 00 00 00 07 B9 11 03 02 40 02 40

					29 00 00 00 00 00 02 ED 44			/* ERR_FG */

					/* TE Start Timing */
					29 00 00 00 00 00 06 B9 01 0A 0E 0A 17

					/* FFC Setting (898Mbps) */
					29 00 00 00 00 00 03 FC 5A 5A		/* TEST KEY2 Enable */
					29 00 00 00 00 00 0E CE 0D 58 1B 43 0A 1C 60 73 00 FF 02 11 0B
					29 00 00 00 00 00 03 FC A5 A5		/* TEST KEY2 Disable */

					29 00 00 00 00 00 05 2A 00 00 04 37	/* CASET PASET */
					29 00 00 00 00 00 05 2B 00 00 07 7F

					0A 01 00 00 0A 00 58				/* PPS setting fhd */
						11 00 00 89 30 80 07
						80 04 38 00 20 02 1C
						02 1C 02 00 02 0E 00
						20 03 15 00 07 00 0C
						03 19 03 2E 18 00 10
						F0 03 0C 20 00 06 0B
						0B 33 0E 1C 2A 38 46
						54 62 69 70 77 79 7B
						7D 7E 01 02 01 00 09
						40 09 BE 19 FC 19 FA
						19 F8 1A 38 1A 78 1A
						B6 2A F6 2B 34 2B 74
						3B 74 6B F4

					29 00 00 00 00 00 02 BA 02			/* scaler setup */

					29 00 00 00 00 00 24				/* Brightness condition set */
						CA
						01 00 01 00 01 00
						80 80 80
						80 80 80
						80 80 80
						80 80 80
						80 80 80
						80 80 80
						80 80 80
						80 80 80
						00 00 00
						00 00
					29 00 00 00 00 00 03 B1 00 0C		/* AID 0% */
					29 00 00 00 00 00 02 B0 01
					29 00 00 00 00 00 03 B5 BC 0A		/* ELVSS Setting:CAPS ON : acl off */
					29 00 00 00 00 00 03 F4 BB 1E		/* VINT set */

					29 01 00 00 01 00 02 F7 03			/* Gamma, LTPS(AID) update wait more 100ns */
					29 00 00 00 00 00 02 F7 00

					29 01 00 00 00 00 02 B0 04
					29 01 00 00 00 00 03 F2 1C 70		/* LDI FPS Recovery(59.835hz) */

					29 01 00 00 00 00 03 F0 A5 A5		/* TEST KEY key Disable  */
				];
				qcom,mdss-dsi-on-command-state = "dsi_lp_mode";
				qcom,panel-roi-alignment=<540 32 540 32 540 32>;
				qcom,compression-mode = "dsc";
				qcom,config-select = <&dsc_fhd>;
				dsc_fhd: config_fhd {
					qcom,lm-split = <540 540>;
					qcom,mdss-dsc-encoders = <2>;
					qcom,mdss-dsc-slice-height = <32>;
					qcom,mdss-dsc-slice-width = <540>;
					qcom,mdss-dsc-slice-per-pkt = <1>;

					qcom,mdss-dsc-bit-per-component = <8>;
					qcom,mdss-dsc-bit-per-pixel = <8>;
					qcom,mdss-dsc-block-prediction-enable;
				};
			};
			hd {
				qcom,mdss-dsi-panel-width = <720>;
				qcom,mdss-dsi-panel-height = <1280>;/*<1080>*/
				qcom,mdss-dsi-h-pulse-width = <52>;
				qcom,mdss-dsi-h-back-porch = <396>;/*<876>;*/
				qcom,mdss-dsi-h-front-porch = <152>;
				qcom,mdss-dsi-h-sync-skew = <0>;
				qcom,mdss-dsi-v-pulse-width = <100>;
				qcom,mdss-dsi-v-back-porch = <160>;
				qcom,mdss-dsi-v-front-porch = <1430>;/*<1630>;*/
				qcom,mdss-dsi-panel-framerate = <60>;
				qcom,mdss-dsi-panel-timings = [FE 56 3C 00 74 88 3C 56 4A 03 04 A0];
				/*qcom,mdss-dsi-timing-switch-command; use samsung,panel_multires_XXX instead*/
				/*qcom,mdss-dsi-timing-switch-command-state;*/
				qcom,mdss-dsi-t-clk-pre = <0x30>;
				qcom,mdss-dsi-t-clk-post = <0x0D>;

				qcom,mdss-dsi-panel-timings-phy-v2 = [
					24 1F 08 09 05 03 04 a0
					24 1F 08 09 05 03 04 a0
					24 1F 08 09 05 03 04 a0
					24 1F 08 09 05 03 04 a0
					24 1B 08 09 05 03 04 a0
				];
				qcom,mdss-dsi-on-command = [
					29 00 00 00 05 00 03 F0 5A 5A		/* TEST KEY1 Enable - 5ms */

					/* DSC setting */
					07 01 00 00 00 00 01 01				/* DSC enable */

					05 01 00 00 78 00 01 11				/* Sleep out (Wait 120ms) */

					/* Sleep out, wait 120 ms */

					29 00 00 00 00 00 02 B0 02
					29 00 00 00 00 00 02 F6 97			/* Source status refresh */

					29 01 00 00 00 00 03 9F A5 A5		/* LV1 (9F) unlock */
					29 00 00 00 00 00 02 35 00			/* TE Vsync ON */
					29 01 00 00 00 00 03 9F 5A 5A		/* LV1 (9F) lock */

					29 00 00 00 00 00 02 B0 05			/* Touch Vsync&Hsync Enable */
					29 00 00 00 00 00 07 B9 11 03 02 40 02 40

					29 00 00 00 00 00 02 ED 44			/* ERR_FG */

					/* TE Start Timing */
					29 00 00 00 00 00 06 B9 01 0A 0E 0A 17

					/* FFC Setting (898Mbps) */
					29 00 00 00 00 00 03 FC 5A 5A		/* TEST KEY2 Enable */
					29 00 00 00 00 00 0E CE 0D 58 1B 43 0A 1C 60 73 00 FF 02 11 0B
					29 00 00 00 00 00 03 FC A5 A5		/* TEST KEY2 Disable */

					29 00 00 00 00 00 05 2A 00 00 02 CF	/* CASET PASET */
					29 00 00 00 00 00 05 2B 00 00 04 FF

					0A 01 00 00 0A 00 58				/* PPS setting hd*/
						11 00 00 89 30 80 05
						00 02 D0 00 40 01 68
						01 68 02 00 01 B4 00
						20 04 F2 00 05 00 0C
						01 87 02 63 18 00 10
						F0 03 0C 20 00 06 0B
						0B 33 0E 1C 2A 38 46
						54 62 69 70 77 79 7B
						7D 7E 01 02 01 00 09
						40 09 BE 19 FC 19 FA
						19 F8 1A 38 1A 78 1A
						B6 2A F6 2B 34 2B 74
						3B 74 6B F4

					29 00 00 00 00 00 02 BA 00			/* scaler setup */

					29 00 00 00 00 00 24				/* Brightness condition set */
						CA
						01 00 01 00 01 00
						80 80 80
						80 80 80
						80 80 80
						80 80 80
						80 80 80
						80 80 80
						80 80 80
						80 80 80
						00 00 00
						00 00
					29 00 00 00 00 00 03 B1 00 0C		/* AID 0% */
					29 00 00 00 00 00 02 B0 01
					29 00 00 00 00 00 03 B5 BC 0A		/* ELVSS Setting:CAPS ON : acl off */
					29 00 00 00 00 00 03 F4 BB 1E		/* VINT set */

					29 01 00 00 01 00 02 F7 03			/* Gamma, LTPS(AID) update wait more 100ns */
					29 00 00 00 00 00 02 F7 00

					29 01 00 00 00 00 02 B0 04
					29 01 00 00 00 00 03 F2 1C 70		/* LDI FPS Recovery(59.835hz) */

					29 01 00 00 00 00 03 F0 A5 A5		/* TEST KEY key Disable  */
				];
				qcom,mdss-dsi-on-command-state = "dsi_lp_mode";
				qcom,panel-roi-alignment=<360 64 360 64 360 64>;
				qcom,compression-mode = "dsc";
				qcom,config-select = <&dsc_hd>;
				dsc_hd: config_hd {
					qcom,lm-split = <360 360>;
					qcom,mdss-dsc-encoders = <2>;
					qcom,mdss-dsc-slice-height = <64>;
					qcom,mdss-dsc-slice-width = <360>;
					qcom,mdss-dsc-slice-per-pkt = <1>;

					qcom,mdss-dsc-bit-per-component = <8>;
					qcom,mdss-dsc-bit-per-pixel = <8>;
					qcom,mdss-dsc-block-prediction-enable;
				};

			};
		};
	};
};
